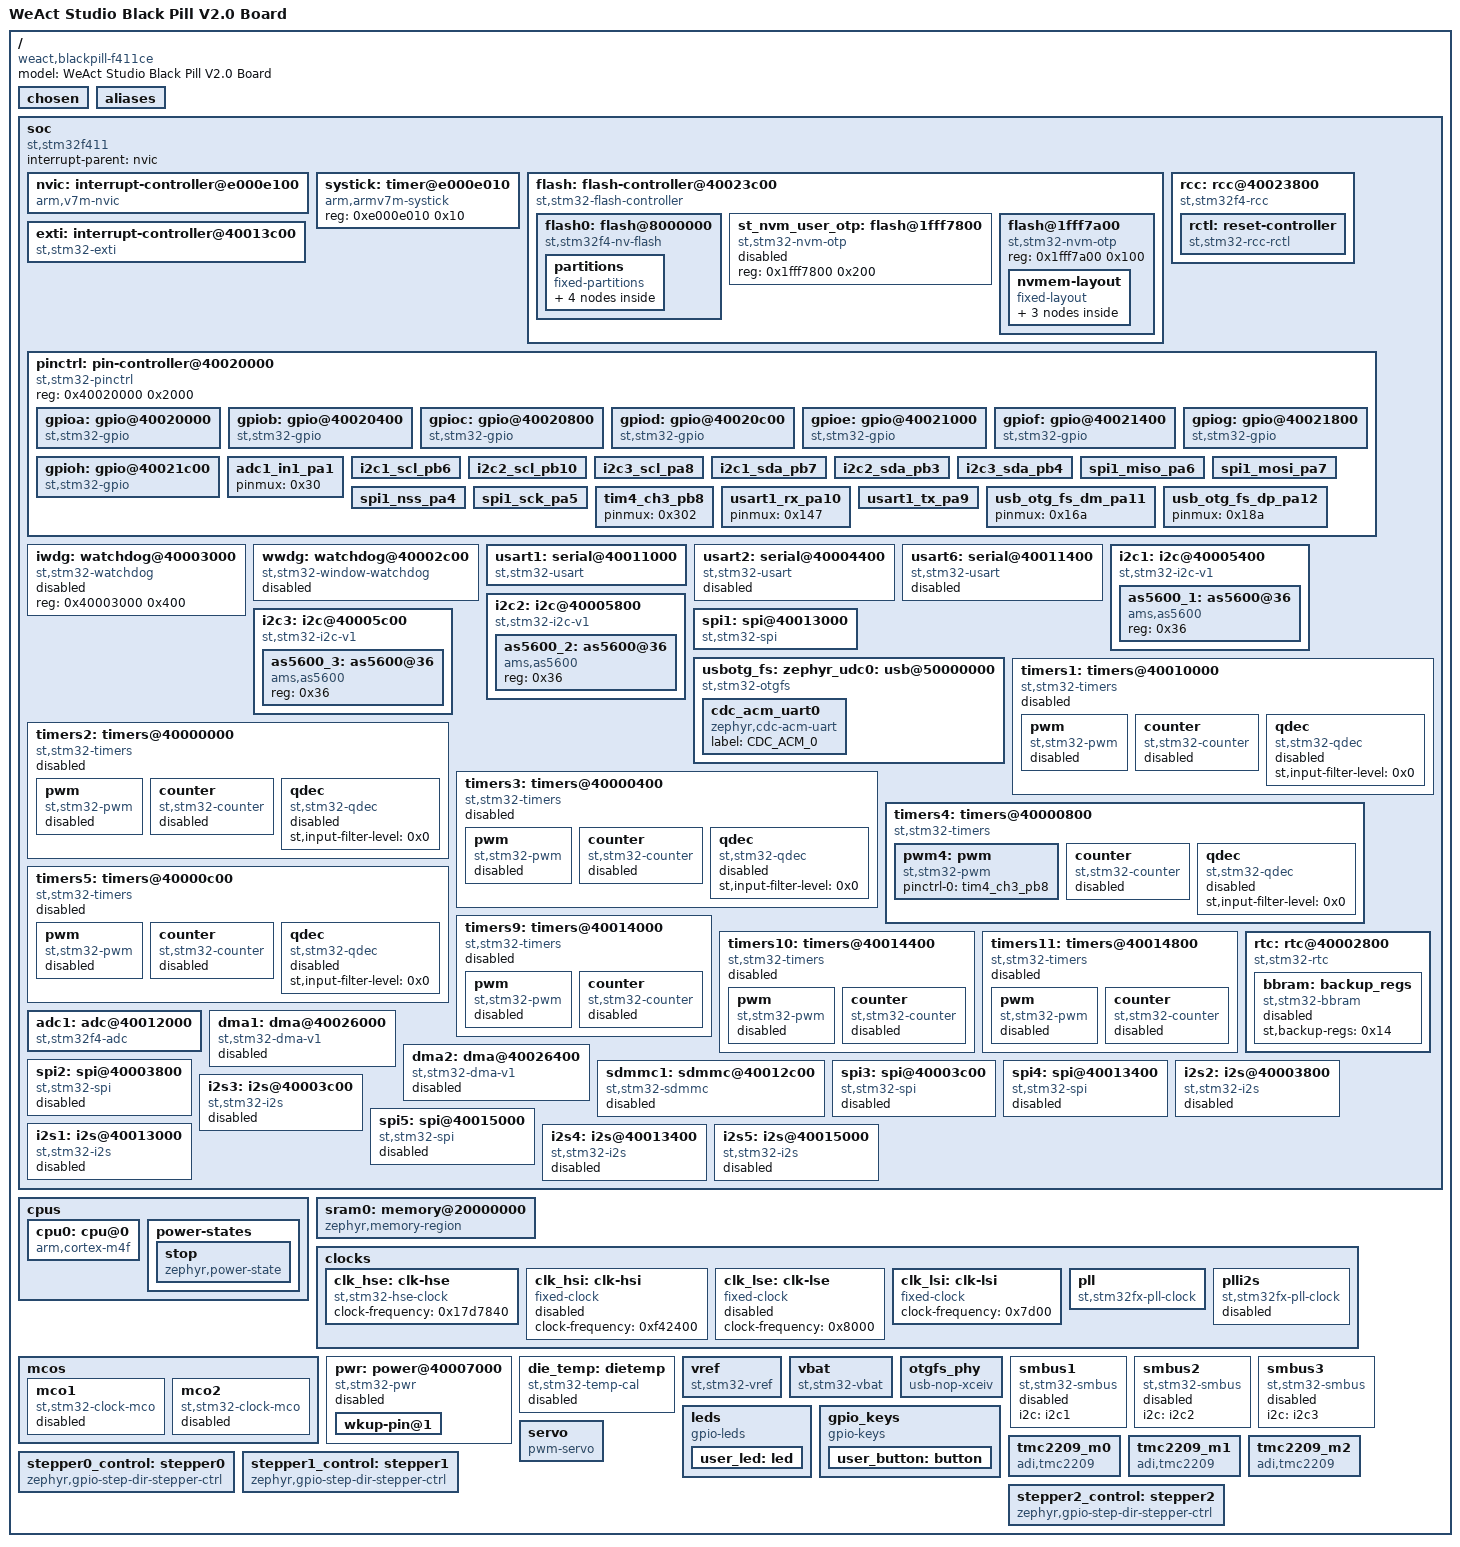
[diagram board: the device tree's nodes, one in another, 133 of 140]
/dts-v1/;

/* node '/' defined in zephyr/dts/common/skeleton.dtsi:9 */
/ {
	#address-cells = < 0x1 >;                     /* in zephyr/dts/common/skeleton.dtsi:10 */
	#size-cells = < 0x1 >;                        /* in zephyr/dts/common/skeleton.dtsi:11 */
	model = "WeAct Studio Black Pill V2.0 Board"; /* in zephyr/boards/weact/blackpill_f411ce/blackpill_f411ce.dts:14 */
	compatible = "weact,blackpill-f411ce";        /* in zephyr/boards/weact/blackpill_f411ce/blackpill_f411ce.dts:15 */

	/* node '/chosen' defined in zephyr/dts/common/skeleton.dtsi:13 */
	chosen {
		zephyr,flash-controller = &flash;     /* in zephyr/dts/arm/st/f4/stm32f4.dtsi:26 */
		zephyr,system-timer-companion = &rtc; /* in zephyr/dts/arm/st/f4/stm32f4.dtsi:27 */
		zephyr,sram = &sram0;                 /* in zephyr/boards/weact/blackpill_f411ce/blackpill_f411ce.dts:20 */
		zephyr,flash = &flash0;               /* in zephyr/boards/weact/blackpill_f411ce/blackpill_f411ce.dts:21 */
		zephyr,console = &cdc_acm_uart0;      /* in joint_microros_tmc2209_gripper_as5600/boards/blackpill_f411ce.overlay:137 */
		zephyr,shell-uart = &cdc_acm_uart0;   /* in joint_microros_tmc2209_gripper_as5600/boards/blackpill_f411ce.overlay:138 */
	};

	/* node '/aliases' defined in zephyr/dts/common/skeleton.dtsi:15 */
	aliases {
		led0 = &user_led;             /* in zephyr/boards/weact/blackpill_f411ce/blackpill_f411ce.dts:44 */
		sw0 = &user_button;           /* in zephyr/boards/weact/blackpill_f411ce/blackpill_f411ce.dts:45 */
		volt-sensor0 = &vref;         /* in zephyr/boards/weact/blackpill_f411ce/blackpill_f411ce.dts:46 */
		volt-sensor1 = &vbat;         /* in zephyr/boards/weact/blackpill_f411ce/blackpill_f411ce.dts:47 */
		stepper0 = &stepper0_control; /* in joint_microros_tmc2209_gripper_as5600/boards/blackpill_f411ce.overlay:82 */
		stepper1 = &stepper1_control; /* in joint_microros_tmc2209_gripper_as5600/boards/blackpill_f411ce.overlay:83 */
		stepper2 = &stepper2_control; /* in joint_microros_tmc2209_gripper_as5600/boards/blackpill_f411ce.overlay:84 */
	};

	/* node '/soc' defined in zephyr/dts/arm/armv7-m.dtsi:6 */
	soc {
		#address-cells = < 0x1 >;     /* in zephyr/dts/arm/armv7-m.dtsi:7 */
		#size-cells = < 0x1 >;        /* in zephyr/dts/arm/armv7-m.dtsi:8 */
		interrupt-parent = < &nvic >; /* in zephyr/dts/arm/armv7-m.dtsi:10 */
		ranges;                       /* in zephyr/dts/arm/armv7-m.dtsi:11 */
		compatible = "st,stm32f411",
		             "st,stm32f4",
		             "simple-bus";    /* in zephyr/dts/arm/st/f4/stm32f411.dtsi:11 */

		/* node '/soc/interrupt-controller@e000e100' defined in zephyr/dts/arm/armv7-m.dtsi:13 */
		nvic: interrupt-controller@e000e100 {
			#address-cells = < 0x1 >;            /* in zephyr/dts/arm/armv7-m.dtsi:14 */
			compatible = "arm,v7m-nvic";         /* in zephyr/dts/arm/armv7-m.dtsi:15 */
			reg = < 0xe000e100 0xc00 >;          /* in zephyr/dts/arm/armv7-m.dtsi:16 */
			interrupt-controller;                /* in zephyr/dts/arm/armv7-m.dtsi:17 */
			#interrupt-cells = < 0x2 >;          /* in zephyr/dts/arm/armv7-m.dtsi:18 */
			arm,num-irq-priority-bits = < 0x4 >; /* in zephyr/dts/arm/st/f4/stm32f4.dtsi:727 */
			phandle = < 0x1 >;                   /* in zephyr/dts/arm/armv7-m.dtsi:10 */
		};

		/* node '/soc/timer@e000e010' defined in zephyr/dts/arm/armv7-m.dtsi:21 */
		systick: timer@e000e010 {
			compatible = "arm,armv7m-systick"; /* in zephyr/dts/arm/armv7-m.dtsi:22 */
			reg = < 0xe000e010 0x10 >;         /* in zephyr/dts/arm/armv7-m.dtsi:23 */
		};

		/* node '/soc/flash-controller@40023c00' defined in zephyr/dts/arm/st/f4/stm32f4.dtsi:112 */
		flash: flash-controller@40023c00 {
			compatible = "st,stm32-flash-controller",
			             "st,stm32f4-flash-controller"; /* in zephyr/dts/arm/st/f4/stm32f4.dtsi:113 */
			reg = < 0x40023c00 0x400 >;                 /* in zephyr/dts/arm/st/f4/stm32f4.dtsi:114 */
			interrupts = < 0x4 0x0 >;                   /* in zephyr/dts/arm/st/f4/stm32f4.dtsi:115 */
			#address-cells = < 0x1 >;                   /* in zephyr/dts/arm/st/f4/stm32f4.dtsi:117 */
			#size-cells = < 0x1 >;                      /* in zephyr/dts/arm/st/f4/stm32f4.dtsi:118 */

			/* node '/soc/flash-controller@40023c00/flash@8000000' defined in zephyr/dts/arm/st/f4/stm32f4.dtsi:120 */
			flash0: flash@8000000 {
				compatible = "st,stm32f4-nv-flash",
				             "st,stm32-nv-flash",
				             "soc-nv-flash";        /* in zephyr/dts/arm/st/f4/stm32f4.dtsi:121 */
				write-block-size = < 0x1 >;         /* in zephyr/dts/arm/st/f4/stm32f4.dtsi:124 */
				max-erase-time = < 0xfa0 >;         /* in zephyr/dts/arm/st/f4/stm32f4.dtsi:126 */
				reg = < 0x8000000 0x80000 >;        /* in zephyr/dts/arm/st/f4/stm32f411Xe.dtsi:17 */

				/* node '/soc/flash-controller@40023c00/flash@8000000/partitions' defined in zephyr/boards/weact/blackpill_f411ce/blackpill_f411ce.dts:52 */
				partitions {
					compatible = "fixed-partitions"; /* in zephyr/boards/weact/blackpill_f411ce/blackpill_f411ce.dts:53 */
					#address-cells = < 0x1 >;        /* in zephyr/boards/weact/blackpill_f411ce/blackpill_f411ce.dts:54 */
					#size-cells = < 0x1 >;           /* in zephyr/boards/weact/blackpill_f411ce/blackpill_f411ce.dts:55 */

					/* node '/soc/flash-controller@40023c00/flash@8000000/partitions/partition@0' defined in zephyr/boards/weact/blackpill_f411ce/blackpill_f411ce.dts:57 */
					boot_partition: partition@0 {
						label = "mcuboot";    /* in zephyr/boards/weact/blackpill_f411ce/blackpill_f411ce.dts:58 */
						reg = < 0x0 0x8000 >; /* in zephyr/boards/weact/blackpill_f411ce/blackpill_f411ce.dts:59 */
						read-only;            /* in zephyr/boards/weact/blackpill_f411ce/blackpill_f411ce.dts:60 */
					};

					/* node '/soc/flash-controller@40023c00/flash@8000000/partitions/partition@20000' defined in zephyr/boards/weact/blackpill_f411ce/blackpill_f411ce.dts:69 */
					slot0_partition: partition@20000 {
						label = "image-0";         /* in zephyr/boards/weact/blackpill_f411ce/blackpill_f411ce.dts:70 */
						reg = < 0x20000 0x20000 >; /* in zephyr/boards/weact/blackpill_f411ce/blackpill_f411ce.dts:71 */
					};

					/* node '/soc/flash-controller@40023c00/flash@8000000/partitions/partition@40000' defined in zephyr/boards/weact/blackpill_f411ce/blackpill_f411ce.dts:74 */
					slot1_partition: partition@40000 {
						label = "image-1";         /* in zephyr/boards/weact/blackpill_f411ce/blackpill_f411ce.dts:75 */
						reg = < 0x40000 0x20000 >; /* in zephyr/boards/weact/blackpill_f411ce/blackpill_f411ce.dts:76 */
					};

					/* node '/soc/flash-controller@40023c00/flash@8000000/partitions/partition@60000' defined in zephyr/boards/weact/blackpill_f411ce/blackpill_f411ce.dts:79 */
					scratch_partition: partition@60000 {
						label = "image-scratch";   /* in zephyr/boards/weact/blackpill_f411ce/blackpill_f411ce.dts:80 */
						reg = < 0x60000 0x20000 >; /* in zephyr/boards/weact/blackpill_f411ce/blackpill_f411ce.dts:81 */
					};
				};
			};

			/* node '/soc/flash-controller@40023c00/flash@1fff7800' defined in zephyr/dts/arm/st/f4/stm32f4.dtsi:129 */
			st_nvm_user_otp: flash@1fff7800 {
				compatible = "st,stm32-nvm-otp"; /* in zephyr/dts/arm/st/f4/stm32f4.dtsi:130 */
				reg = < 0x1fff7800 0x200 >;      /* in zephyr/dts/arm/st/f4/stm32f4.dtsi:131 */
				status = "disabled";             /* in zephyr/dts/arm/st/f4/stm32f4.dtsi:132 */
			};

			/* node '/soc/flash-controller@40023c00/flash@1fff7a00' defined in zephyr/dts/arm/st/f4/stm32f4.dtsi:146 */
			flash@1fff7a00 {
				compatible = "st,stm32-nvm-otp"; /* in zephyr/dts/arm/st/f4/stm32f4.dtsi:147 */
				reg = < 0x1fff7a00 0x100 >;      /* in zephyr/dts/arm/st/f4/stm32f4.dtsi:148 */

				/* node '/soc/flash-controller@40023c00/flash@1fff7a00/nvmem-layout' defined in zephyr/dts/arm/st/f4/stm32f4.dtsi:150 */
				nvmem-layout {
					compatible = "fixed-layout"; /* in zephyr/dts/arm/st/f4/stm32f4.dtsi:151 */
					#address-cells = < 0x1 >;    /* in zephyr/dts/arm/st/f4/stm32f4.dtsi:152 */
					#size-cells = < 0x1 >;       /* in zephyr/dts/arm/st/f4/stm32f4.dtsi:153 */

					/* node '/soc/flash-controller@40023c00/flash@1fff7a00/nvmem-layout/vrefint@2a' defined in zephyr/dts/arm/st/f4/stm32f4.dtsi:155 */
					vrefint_otp: vrefint@2a {
						reg = < 0x2a 0x2 >;          /* in zephyr/dts/arm/st/f4/stm32f4.dtsi:156 */
						#nvmem-cell-cells = < 0x0 >; /* in zephyr/dts/arm/st/f4/stm32f4.dtsi:157 */
						read-only;                   /* in zephyr/dts/arm/st/f4/stm32f4.dtsi:158 */
						phandle = < 0x1e >;          /* in zephyr/dts/arm/st/f4/stm32f4.dtsi:683 */
					};

					/* node '/soc/flash-controller@40023c00/flash@1fff7a00/nvmem-layout/ts-cal1@2c' defined in zephyr/dts/arm/st/f4/stm32f4.dtsi:161 */
					ts_cal1_otp: ts-cal1@2c {
						reg = < 0x2c 0x2 >;          /* in zephyr/dts/arm/st/f4/stm32f4.dtsi:162 */
						#nvmem-cell-cells = < 0x0 >; /* in zephyr/dts/arm/st/f4/stm32f4.dtsi:163 */
						read-only;                   /* in zephyr/dts/arm/st/f4/stm32f4.dtsi:164 */
						phandle = < 0x1b >;          /* in zephyr/dts/arm/st/f4/stm32f4.dtsi:672 */
					};

					/* node '/soc/flash-controller@40023c00/flash@1fff7a00/nvmem-layout/ts-cal2@2e' defined in zephyr/dts/arm/st/f4/stm32f4.dtsi:167 */
					ts_cal2_otp: ts-cal2@2e {
						reg = < 0x2e 0x2 >;          /* in zephyr/dts/arm/st/f4/stm32f4.dtsi:168 */
						#nvmem-cell-cells = < 0x0 >; /* in zephyr/dts/arm/st/f4/stm32f4.dtsi:169 */
						read-only;                   /* in zephyr/dts/arm/st/f4/stm32f4.dtsi:170 */
						phandle = < 0x1c >;          /* in zephyr/dts/arm/st/f4/stm32f4.dtsi:672 */
					};
				};
			};
		};

		/* node '/soc/rcc@40023800' defined in zephyr/dts/arm/st/f4/stm32f4.dtsi:176 */
		rcc: rcc@40023800 {
			compatible = "st,stm32f4-rcc";   /* in zephyr/dts/arm/st/f4/stm32f4.dtsi:177 */
			#clock-cells = < 0x2 >;          /* in zephyr/dts/arm/st/f4/stm32f4.dtsi:178 */
			reg = < 0x40023800 0x400 >;      /* in zephyr/dts/arm/st/f4/stm32f4.dtsi:179 */
			clocks = < &pll >;               /* in zephyr/boards/weact/blackpill_f411ce/blackpill_f411ce.dts:156 */
			clock-frequency = < 0x5b8d800 >; /* in zephyr/boards/weact/blackpill_f411ce/blackpill_f411ce.dts:157 */
			ahb-prescaler = < 0x1 >;         /* in zephyr/boards/weact/blackpill_f411ce/blackpill_f411ce.dts:158 */
			apb1-prescaler = < 0x2 >;        /* in zephyr/boards/weact/blackpill_f411ce/blackpill_f411ce.dts:159 */
			apb2-prescaler = < 0x1 >;        /* in zephyr/boards/weact/blackpill_f411ce/blackpill_f411ce.dts:160 */
			phandle = < 0x3 >;               /* in zephyr/dts/arm/st/f4/stm32f4.dtsi:193 */

			/* node '/soc/rcc@40023800/reset-controller' defined in zephyr/dts/arm/st/f4/stm32f4.dtsi:181 */
			rctl: reset-controller {
				compatible = "st,stm32-rcc-rctl"; /* in zephyr/dts/arm/st/f4/stm32f4.dtsi:182 */
				#reset-cells = < 0x1 >;           /* in zephyr/dts/arm/st/f4/stm32f4.dtsi:183 */
				phandle = < 0x4 >;                /* in zephyr/dts/arm/st/f4/stm32f4.dtsi:292 */
			};
		};

		/* node '/soc/interrupt-controller@40013c00' defined in zephyr/dts/arm/st/f4/stm32f4.dtsi:187 */
		exti: interrupt-controller@40013c00 {
			compatible = "st,stm32-exti";  /* in zephyr/dts/arm/st/f4/stm32f4.dtsi:188 */
			interrupt-controller;          /* in zephyr/dts/arm/st/f4/stm32f4.dtsi:189 */
			#interrupt-cells = < 0x1 >;    /* in zephyr/dts/arm/st/f4/stm32f4.dtsi:190 */
			#address-cells = < 0x0 >;      /* in zephyr/dts/arm/st/f4/stm32f4.dtsi:191 */
			reg = < 0x40013c00 0x400 >;    /* in zephyr/dts/arm/st/f4/stm32f4.dtsi:192 */
			clocks = < &rcc 0x44 0x4000 >; /* in zephyr/dts/arm/st/f4/stm32f4.dtsi:193 */
			num-lines = < 0x20 >;          /* in zephyr/dts/arm/st/f4/stm32f4.dtsi:194 */
			interrupts = < 0x6 0x0 >,
			             < 0x7 0x0 >,
			             < 0x8 0x0 >,
			             < 0x9 0x0 >,
			             < 0xa 0x0 >,
			             < 0x17 0x0 >,
			             < 0x28 0x0 >;     /* in zephyr/dts/arm/st/f4/stm32f4.dtsi:195 */
			interrupt-names = "line0",
			                  "line1",
			                  "line2",
			                  "line3",
			                  "line4",
			                  "line5-9",
			                  "line10-15"; /* in zephyr/dts/arm/st/f4/stm32f4.dtsi:197 */
			line-ranges = < 0x0 0x1 >,
			              < 0x1 0x1 >,
			              < 0x2 0x1 >,
			              < 0x3 0x1 >,
			              < 0x4 0x1 >,
			              < 0x5 0x5 >,
			              < 0xa 0x6 >;     /* in zephyr/dts/arm/st/f4/stm32f4.dtsi:199 */
		};

		/* node '/soc/pin-controller@40020000' defined in zephyr/dts/arm/st/f4/stm32f4.dtsi:203 */
		pinctrl: pin-controller@40020000 {
			compatible = "st,stm32-pinctrl"; /* in zephyr/dts/arm/st/f4/stm32f4.dtsi:204 */
			#address-cells = < 0x1 >;        /* in zephyr/dts/arm/st/f4/stm32f4.dtsi:205 */
			#size-cells = < 0x1 >;           /* in zephyr/dts/arm/st/f4/stm32f4.dtsi:206 */
			reg = < 0x40020000 0x2000 >;     /* in zephyr/dts/arm/st/f4/stm32f4.dtsi:207 */

			/* node '/soc/pin-controller@40020000/gpio@40020000' defined in zephyr/dts/arm/st/f4/stm32f4.dtsi:209 */
			gpioa: gpio@40020000 {
				compatible = "st,stm32-gpio"; /* in zephyr/dts/arm/st/f4/stm32f4.dtsi:210 */
				gpio-controller;              /* in zephyr/dts/arm/st/f4/stm32f4.dtsi:211 */
				#gpio-cells = < 0x2 >;        /* in zephyr/dts/arm/st/f4/stm32f4.dtsi:212 */
				reg = < 0x40020000 0x400 >;   /* in zephyr/dts/arm/st/f4/stm32f4.dtsi:213 */
				clocks = < &rcc 0x30 0x1 >;   /* in zephyr/dts/arm/st/f4/stm32f4.dtsi:214 */
				phandle = < 0x1a >;           /* in zephyr/dts/arm/st/f4/stm32f4.dtsi:666 */
			};

			/* node '/soc/pin-controller@40020000/gpio@40020400' defined in zephyr/dts/arm/st/f4/stm32f4.dtsi:217 */
			gpiob: gpio@40020400 {
				compatible = "st,stm32-gpio"; /* in zephyr/dts/arm/st/f4/stm32f4.dtsi:218 */
				gpio-controller;              /* in zephyr/dts/arm/st/f4/stm32f4.dtsi:219 */
				#gpio-cells = < 0x2 >;        /* in zephyr/dts/arm/st/f4/stm32f4.dtsi:220 */
				reg = < 0x40020400 0x400 >;   /* in zephyr/dts/arm/st/f4/stm32f4.dtsi:221 */
				clocks = < &rcc 0x30 0x2 >;   /* in zephyr/dts/arm/st/f4/stm32f4.dtsi:222 */
			};

			/* node '/soc/pin-controller@40020000/gpio@40020800' defined in zephyr/dts/arm/st/f4/stm32f4.dtsi:225 */
			gpioc: gpio@40020800 {
				compatible = "st,stm32-gpio"; /* in zephyr/dts/arm/st/f4/stm32f4.dtsi:226 */
				gpio-controller;              /* in zephyr/dts/arm/st/f4/stm32f4.dtsi:227 */
				#gpio-cells = < 0x2 >;        /* in zephyr/dts/arm/st/f4/stm32f4.dtsi:228 */
				reg = < 0x40020800 0x400 >;   /* in zephyr/dts/arm/st/f4/stm32f4.dtsi:229 */
				clocks = < &rcc 0x30 0x4 >;   /* in zephyr/dts/arm/st/f4/stm32f4.dtsi:230 */
				phandle = < 0x22 >;           /* in zephyr/boards/weact/blackpill_f411ce/blackpill_f411ce.dts:28 */
			};

			/* node '/soc/pin-controller@40020000/gpio@40020c00' defined in zephyr/dts/arm/st/f4/stm32f4.dtsi:233 */
			gpiod: gpio@40020c00 {
				compatible = "st,stm32-gpio"; /* in zephyr/dts/arm/st/f4/stm32f4.dtsi:234 */
				gpio-controller;              /* in zephyr/dts/arm/st/f4/stm32f4.dtsi:235 */
				#gpio-cells = < 0x2 >;        /* in zephyr/dts/arm/st/f4/stm32f4.dtsi:236 */
				reg = < 0x40020c00 0x400 >;   /* in zephyr/dts/arm/st/f4/stm32f4.dtsi:237 */
				clocks = < &rcc 0x30 0x8 >;   /* in zephyr/dts/arm/st/f4/stm32f4.dtsi:238 */
			};

			/* node '/soc/pin-controller@40020000/gpio@40021000' defined in zephyr/dts/arm/st/f4/stm32f4.dtsi:241 */
			gpioe: gpio@40021000 {
				compatible = "st,stm32-gpio"; /* in zephyr/dts/arm/st/f4/stm32f4.dtsi:242 */
				gpio-controller;              /* in zephyr/dts/arm/st/f4/stm32f4.dtsi:243 */
				#gpio-cells = < 0x2 >;        /* in zephyr/dts/arm/st/f4/stm32f4.dtsi:244 */
				reg = < 0x40021000 0x400 >;   /* in zephyr/dts/arm/st/f4/stm32f4.dtsi:245 */
				clocks = < &rcc 0x30 0x10 >;  /* in zephyr/dts/arm/st/f4/stm32f4.dtsi:246 */
			};

			/* node '/soc/pin-controller@40020000/gpio@40021400' defined in zephyr/dts/arm/st/f4/stm32f4.dtsi:249 */
			gpiof: gpio@40021400 {
				compatible = "st,stm32-gpio"; /* in zephyr/dts/arm/st/f4/stm32f4.dtsi:250 */
				gpio-controller;              /* in zephyr/dts/arm/st/f4/stm32f4.dtsi:251 */
				#gpio-cells = < 0x2 >;        /* in zephyr/dts/arm/st/f4/stm32f4.dtsi:252 */
				reg = < 0x40021400 0x400 >;   /* in zephyr/dts/arm/st/f4/stm32f4.dtsi:253 */
				clocks = < &rcc 0x30 0x20 >;  /* in zephyr/dts/arm/st/f4/stm32f4.dtsi:254 */
			};

			/* node '/soc/pin-controller@40020000/gpio@40021800' defined in zephyr/dts/arm/st/f4/stm32f4.dtsi:257 */
			gpiog: gpio@40021800 {
				compatible = "st,stm32-gpio"; /* in zephyr/dts/arm/st/f4/stm32f4.dtsi:258 */
				gpio-controller;              /* in zephyr/dts/arm/st/f4/stm32f4.dtsi:259 */
				#gpio-cells = < 0x2 >;        /* in zephyr/dts/arm/st/f4/stm32f4.dtsi:260 */
				reg = < 0x40021800 0x400 >;   /* in zephyr/dts/arm/st/f4/stm32f4.dtsi:261 */
				clocks = < &rcc 0x30 0x40 >;  /* in zephyr/dts/arm/st/f4/stm32f4.dtsi:262 */
			};

			/* node '/soc/pin-controller@40020000/gpio@40021c00' defined in zephyr/dts/arm/st/f4/stm32f4.dtsi:265 */
			gpioh: gpio@40021c00 {
				compatible = "st,stm32-gpio"; /* in zephyr/dts/arm/st/f4/stm32f4.dtsi:266 */
				gpio-controller;              /* in zephyr/dts/arm/st/f4/stm32f4.dtsi:267 */
				#gpio-cells = < 0x2 >;        /* in zephyr/dts/arm/st/f4/stm32f4.dtsi:268 */
				reg = < 0x40021c00 0x400 >;   /* in zephyr/dts/arm/st/f4/stm32f4.dtsi:269 */
				clocks = < &rcc 0x30 0x80 >;  /* in zephyr/dts/arm/st/f4/stm32f4.dtsi:270 */
			};

			/* node '/soc/pin-controller@40020000/adc1_in1_pa1' defined in modules/hal/stm32/dts/st/f4/stm32f411c(c-e)ux-pinctrl.dtsi:17 */
			adc1_in1_pa1: adc1_in1_pa1 {
				pinmux = < 0x30 >;  /* in modules/hal/stm32/dts/st/f4/stm32f411c(c-e)ux-pinctrl.dtsi:18 */
				phandle = < 0x15 >; /* in zephyr/boards/weact/blackpill_f411ce/blackpill_f411ce.dts:130 */
			};

			/* node '/soc/pin-controller@40020000/i2c1_scl_pb6' defined in modules/hal/stm32/dts/st/f4/stm32f411c(c-e)ux-pinctrl.dtsi:201 */
			i2c1_scl_pb6: i2c1_scl_pb6 {
				pinmux = < 0x2c4 >; /* in modules/hal/stm32/dts/st/f4/stm32f411c(c-e)ux-pinctrl.dtsi:202 */
				bias-pull-up;       /* in modules/hal/stm32/dts/st/f4/stm32f411c(c-e)ux-pinctrl.dtsi:203 */
				drive-open-drain;   /* in modules/hal/stm32/dts/st/f4/stm32f411c(c-e)ux-pinctrl.dtsi:204 */
				phandle = < 0x7 >;  /* in joint_microros_tmc2209_gripper_as5600/boards/blackpill_f411ce.overlay:22 */
			};

			/* node '/soc/pin-controller@40020000/i2c2_scl_pb10' defined in modules/hal/stm32/dts/st/f4/stm32f411c(c-e)ux-pinctrl.dtsi:213 */
			i2c2_scl_pb10: i2c2_scl_pb10 {
				pinmux = < 0x344 >; /* in modules/hal/stm32/dts/st/f4/stm32f411c(c-e)ux-pinctrl.dtsi:214 */
				bias-pull-up;       /* in modules/hal/stm32/dts/st/f4/stm32f411c(c-e)ux-pinctrl.dtsi:215 */
				drive-open-drain;   /* in modules/hal/stm32/dts/st/f4/stm32f411c(c-e)ux-pinctrl.dtsi:216 */
				phandle = < 0x9 >;  /* in joint_microros_tmc2209_gripper_as5600/boards/blackpill_f411ce.overlay:34 */
			};

			/* node '/soc/pin-controller@40020000/i2c3_scl_pa8' defined in modules/hal/stm32/dts/st/f4/stm32f411c(c-e)ux-pinctrl.dtsi:219 */
			i2c3_scl_pa8: i2c3_scl_pa8 {
				pinmux = < 0x104 >; /* in modules/hal/stm32/dts/st/f4/stm32f411c(c-e)ux-pinctrl.dtsi:220 */
				bias-pull-up;       /* in modules/hal/stm32/dts/st/f4/stm32f411c(c-e)ux-pinctrl.dtsi:221 */
				drive-open-drain;   /* in modules/hal/stm32/dts/st/f4/stm32f411c(c-e)ux-pinctrl.dtsi:222 */
				phandle = < 0xb >;  /* in joint_microros_tmc2209_gripper_as5600/boards/blackpill_f411ce.overlay:47 */
			};

			/* node '/soc/pin-controller@40020000/i2c1_sda_pb7' defined in modules/hal/stm32/dts/st/f4/stm32f411c(c-e)ux-pinctrl.dtsi:227 */
			i2c1_sda_pb7: i2c1_sda_pb7 {
				pinmux = < 0x2e4 >; /* in modules/hal/stm32/dts/st/f4/stm32f411c(c-e)ux-pinctrl.dtsi:228 */
				bias-pull-up;       /* in modules/hal/stm32/dts/st/f4/stm32f411c(c-e)ux-pinctrl.dtsi:229 */
				drive-open-drain;   /* in modules/hal/stm32/dts/st/f4/stm32f411c(c-e)ux-pinctrl.dtsi:230 */
				phandle = < 0x8 >;  /* in joint_microros_tmc2209_gripper_as5600/boards/blackpill_f411ce.overlay:22 */
			};

			/* node '/soc/pin-controller@40020000/i2c2_sda_pb3' defined in modules/hal/stm32/dts/st/f4/stm32f411c(c-e)ux-pinctrl.dtsi:239 */
			i2c2_sda_pb3: i2c2_sda_pb3 {
				pinmux = < 0x269 >; /* in modules/hal/stm32/dts/st/f4/stm32f411c(c-e)ux-pinctrl.dtsi:240 */
				bias-pull-up;       /* in modules/hal/stm32/dts/st/f4/stm32f411c(c-e)ux-pinctrl.dtsi:241 */
				drive-open-drain;   /* in modules/hal/stm32/dts/st/f4/stm32f411c(c-e)ux-pinctrl.dtsi:242 */
				phandle = < 0xa >;  /* in joint_microros_tmc2209_gripper_as5600/boards/blackpill_f411ce.overlay:34 */
			};

			/* node '/soc/pin-controller@40020000/i2c3_sda_pb4' defined in modules/hal/stm32/dts/st/f4/stm32f411c(c-e)ux-pinctrl.dtsi:251 */
			i2c3_sda_pb4: i2c3_sda_pb4 {
				pinmux = < 0x289 >; /* in modules/hal/stm32/dts/st/f4/stm32f411c(c-e)ux-pinctrl.dtsi:252 */
				bias-pull-up;       /* in modules/hal/stm32/dts/st/f4/stm32f411c(c-e)ux-pinctrl.dtsi:253 */
				drive-open-drain;   /* in modules/hal/stm32/dts/st/f4/stm32f411c(c-e)ux-pinctrl.dtsi:254 */
				phandle = < 0xc >;  /* in joint_microros_tmc2209_gripper_as5600/boards/blackpill_f411ce.overlay:47 */
			};

			/* node '/soc/pin-controller@40020000/spi1_miso_pa6' defined in modules/hal/stm32/dts/st/f4/stm32f411c(c-e)ux-pinctrl.dtsi:502 */
			spi1_miso_pa6: spi1_miso_pa6 {
				pinmux = < 0xc5 >;             /* in modules/hal/stm32/dts/st/f4/stm32f411c(c-e)ux-pinctrl.dtsi:503 */
				bias-pull-down;                /* in modules/hal/stm32/dts/st/f4/stm32f411c(c-e)ux-pinctrl.dtsi:504 */
				slew-rate = "very-high-speed"; /* in modules/hal/stm32/dts/st/f4/stm32f411c(c-e)ux-pinctrl.dtsi:505 */
				phandle = < 0xf >;             /* in zephyr/boards/weact/blackpill_f411ce/blackpill_f411ce.dts:111 */
			};

			/* node '/soc/pin-controller@40020000/spi1_mosi_pa7' defined in modules/hal/stm32/dts/st/f4/stm32f411c(c-e)ux-pinctrl.dtsi:540 */
			spi1_mosi_pa7: spi1_mosi_pa7 {
				pinmux = < 0xe5 >;             /* in modules/hal/stm32/dts/st/f4/stm32f411c(c-e)ux-pinctrl.dtsi:541 */
				bias-pull-down;                /* in modules/hal/stm32/dts/st/f4/stm32f411c(c-e)ux-pinctrl.dtsi:542 */
				slew-rate = "very-high-speed"; /* in modules/hal/stm32/dts/st/f4/stm32f411c(c-e)ux-pinctrl.dtsi:543 */
				phandle = < 0x10 >;            /* in zephyr/boards/weact/blackpill_f411ce/blackpill_f411ce.dts:111 */
			};

			/* node '/soc/pin-controller@40020000/spi1_nss_pa4' defined in modules/hal/stm32/dts/st/f4/stm32f411c(c-e)ux-pinctrl.dtsi:584 */
			spi1_nss_pa4: spi1_nss_pa4 {
				pinmux = < 0x85 >;             /* in modules/hal/stm32/dts/st/f4/stm32f411c(c-e)ux-pinctrl.dtsi:585 */
				bias-pull-up;                  /* in modules/hal/stm32/dts/st/f4/stm32f411c(c-e)ux-pinctrl.dtsi:586 */
				slew-rate = "very-high-speed"; /* in modules/hal/stm32/dts/st/f4/stm32f411c(c-e)ux-pinctrl.dtsi:587 */
				phandle = < 0xe >;             /* in zephyr/boards/weact/blackpill_f411ce/blackpill_f411ce.dts:111 */
			};

			/* node '/soc/pin-controller@40020000/spi1_sck_pa5' defined in modules/hal/stm32/dts/st/f4/stm32f411c(c-e)ux-pinctrl.dtsi:634 */
			spi1_sck_pa5: spi1_sck_pa5 {
				pinmux = < 0xa5 >;             /* in modules/hal/stm32/dts/st/f4/stm32f411c(c-e)ux-pinctrl.dtsi:635 */
				bias-pull-down;                /* in modules/hal/stm32/dts/st/f4/stm32f411c(c-e)ux-pinctrl.dtsi:636 */
				slew-rate = "very-high-speed"; /* in modules/hal/stm32/dts/st/f4/stm32f411c(c-e)ux-pinctrl.dtsi:637 */
				phandle = < 0xd >;             /* in zephyr/boards/weact/blackpill_f411ce/blackpill_f411ce.dts:111 */
			};

			/* node '/soc/pin-controller@40020000/tim4_ch3_pb8' defined in modules/hal/stm32/dts/st/f4/stm32f411c(c-e)ux-pinctrl.dtsi:806 */
			tim4_ch3_pb8: tim4_ch3_pb8 {
				pinmux = < 0x302 >; /* in joint_microros_tmc2209_gripper_as5600/boards/blackpill_f411ce.overlay:63 */
				phandle = < 0x14 >; /* in joint_microros_tmc2209_gripper_as5600/boards/blackpill_f411ce.overlay:73 */
			};

			/* node '/soc/pin-controller@40020000/usart1_rx_pa10' defined in modules/hal/stm32/dts/st/f4/stm32f411c(c-e)ux-pinctrl.dtsi:864 */
			usart1_rx_pa10: usart1_rx_pa10 {
				pinmux = < 0x147 >; /* in modules/hal/stm32/dts/st/f4/stm32f411c(c-e)ux-pinctrl.dtsi:865 */
				phandle = < 0x6 >;  /* in zephyr/boards/weact/blackpill_f411ce/blackpill_f411ce.dts:97 */
			};

			/* node '/soc/pin-controller@40020000/usart1_tx_pa9' defined in modules/hal/stm32/dts/st/f4/stm32f411c(c-e)ux-pinctrl.dtsi:886 */
			usart1_tx_pa9: usart1_tx_pa9 {
				pinmux = < 0x127 >; /* in modules/hal/stm32/dts/st/f4/stm32f411c(c-e)ux-pinctrl.dtsi:887 */
				bias-pull-up;       /* in modules/hal/stm32/dts/st/f4/stm32f411c(c-e)ux-pinctrl.dtsi:888 */
				phandle = < 0x5 >;  /* in zephyr/boards/weact/blackpill_f411ce/blackpill_f411ce.dts:97 */
			};

			/* node '/soc/pin-controller@40020000/usb_otg_fs_dm_pa11' defined in modules/hal/stm32/dts/st/f4/stm32f411c(c-e)ux-pinctrl.dtsi:925 */
			usb_otg_fs_dm_pa11: usb_otg_fs_dm_pa11 {
				pinmux = < 0x16a >; /* in modules/hal/stm32/dts/st/f4/stm32f411c(c-e)ux-pinctrl.dtsi:926 */
				phandle = < 0x12 >; /* in joint_microros_tmc2209_gripper_as5600/boards/blackpill_f411ce.overlay:145 */
			};

			/* node '/soc/pin-controller@40020000/usb_otg_fs_dp_pa12' defined in modules/hal/stm32/dts/st/f4/stm32f411c(c-e)ux-pinctrl.dtsi:929 */
			usb_otg_fs_dp_pa12: usb_otg_fs_dp_pa12 {
				pinmux = < 0x18a >; /* in modules/hal/stm32/dts/st/f4/stm32f411c(c-e)ux-pinctrl.dtsi:930 */
				phandle = < 0x13 >; /* in joint_microros_tmc2209_gripper_as5600/boards/blackpill_f411ce.overlay:145 */
			};
		};

		/* node '/soc/watchdog@40003000' defined in zephyr/dts/arm/st/f4/stm32f4.dtsi:274 */
		iwdg: watchdog@40003000 {
			compatible = "st,stm32-watchdog"; /* in zephyr/dts/arm/st/f4/stm32f4.dtsi:275 */
			reg = < 0x40003000 0x400 >;       /* in zephyr/dts/arm/st/f4/stm32f4.dtsi:276 */
			status = "disabled";              /* in zephyr/dts/arm/st/f4/stm32f4.dtsi:277 */
		};

		/* node '/soc/watchdog@40002c00' defined in zephyr/dts/arm/st/f4/stm32f4.dtsi:280 */
		wwdg: watchdog@40002c00 {
			compatible = "st,stm32-window-watchdog"; /* in zephyr/dts/arm/st/f4/stm32f4.dtsi:281 */
			reg = < 0x40002c00 0x400 >;              /* in zephyr/dts/arm/st/f4/stm32f4.dtsi:282 */
			clocks = < &rcc 0x40 0x800 >;            /* in zephyr/dts/arm/st/f4/stm32f4.dtsi:283 */
			interrupts = < 0x0 0x7 >;                /* in zephyr/dts/arm/st/f4/stm32f4.dtsi:284 */
			status = "disabled";                     /* in zephyr/dts/arm/st/f4/stm32f4.dtsi:285 */
		};

		/* node '/soc/serial@40011000' defined in zephyr/dts/arm/st/f4/stm32f4.dtsi:288 */
		usart1: serial@40011000 {
			compatible = "st,stm32-usart",
			             "st,stm32-uart";                   /* in zephyr/dts/arm/st/f4/stm32f4.dtsi:289 */
			reg = < 0x40011000 0x400 >;                     /* in zephyr/dts/arm/st/f4/stm32f4.dtsi:290 */
			clocks = < &rcc 0x44 0x10 >;                    /* in zephyr/dts/arm/st/f4/stm32f4.dtsi:291 */
			resets = < &rctl 0x484 >;                       /* in zephyr/dts/arm/st/f4/stm32f4.dtsi:292 */
			interrupts = < 0x25 0x0 >;                      /* in zephyr/dts/arm/st/f4/stm32f4.dtsi:293 */
			pinctrl-0 = < &usart1_tx_pa9 &usart1_rx_pa10 >; /* in zephyr/boards/weact/blackpill_f411ce/blackpill_f411ce.dts:97 */
			pinctrl-names = "default";                      /* in zephyr/boards/weact/blackpill_f411ce/blackpill_f411ce.dts:98 */
			status = "okay";                                /* in zephyr/boards/weact/blackpill_f411ce/blackpill_f411ce.dts:99 */
			current-speed = < 0x1c200 >;                    /* in zephyr/boards/weact/blackpill_f411ce/blackpill_f411ce.dts:100 */
		};

		/* node '/soc/serial@40004400' defined in zephyr/dts/arm/st/f4/stm32f4.dtsi:297 */
		usart2: serial@40004400 {
			compatible = "st,stm32-usart",
			             "st,stm32-uart";   /* in zephyr/dts/arm/st/f4/stm32f4.dtsi:298 */
			reg = < 0x40004400 0x400 >;     /* in zephyr/dts/arm/st/f4/stm32f4.dtsi:299 */
			clocks = < &rcc 0x40 0x20000 >; /* in zephyr/dts/arm/st/f4/stm32f4.dtsi:300 */
			resets = < &rctl 0x411 >;       /* in zephyr/dts/arm/st/f4/stm32f4.dtsi:301 */
			interrupts = < 0x26 0x0 >;      /* in zephyr/dts/arm/st/f4/stm32f4.dtsi:302 */
			status = "disabled";            /* in zephyr/dts/arm/st/f4/stm32f4.dtsi:303 */
		};

		/* node '/soc/serial@40011400' defined in zephyr/dts/arm/st/f4/stm32f4.dtsi:306 */
		usart6: serial@40011400 {
			compatible = "st,stm32-usart",
			             "st,stm32-uart";  /* in zephyr/dts/arm/st/f4/stm32f4.dtsi:307 */
			reg = < 0x40011400 0x400 >;    /* in zephyr/dts/arm/st/f4/stm32f4.dtsi:308 */
			clocks = < &rcc 0x44 0x20 >;   /* in zephyr/dts/arm/st/f4/stm32f4.dtsi:309 */
			resets = < &rctl 0x485 >;      /* in zephyr/dts/arm/st/f4/stm32f4.dtsi:310 */
			interrupts = < 0x47 0x0 >;     /* in zephyr/dts/arm/st/f4/stm32f4.dtsi:311 */
			status = "disabled";           /* in zephyr/dts/arm/st/f4/stm32f4.dtsi:312 */
		};

		/* node '/soc/i2c@40005400' defined in zephyr/dts/arm/st/f4/stm32f4.dtsi:315 */
		i2c1: i2c@40005400 {
			compatible = "st,stm32-i2c-v1";              /* in zephyr/dts/arm/st/f4/stm32f4.dtsi:316 */
			#address-cells = < 0x1 >;                    /* in zephyr/dts/arm/st/f4/stm32f4.dtsi:318 */
			#size-cells = < 0x0 >;                       /* in zephyr/dts/arm/st/f4/stm32f4.dtsi:319 */
			reg = < 0x40005400 0x400 >;                  /* in zephyr/dts/arm/st/f4/stm32f4.dtsi:320 */
			clocks = < &rcc 0x40 0x200000 >;             /* in zephyr/dts/arm/st/f4/stm32f4.dtsi:321 */
			interrupts = < 0x1f 0x0 >,
			             < 0x20 0x0 >;                   /* in zephyr/dts/arm/st/f4/stm32f4.dtsi:322 */
			interrupt-names = "event",
			                  "error";                   /* in zephyr/dts/arm/st/f4/stm32f4.dtsi:323 */
			status = "okay";                             /* in joint_microros_tmc2209_gripper_as5600/boards/blackpill_f411ce.overlay:21 */
			pinctrl-0 = < &i2c1_scl_pb6 &i2c1_sda_pb7 >; /* in joint_microros_tmc2209_gripper_as5600/boards/blackpill_f411ce.overlay:22 */
			pinctrl-names = "default";                   /* in joint_microros_tmc2209_gripper_as5600/boards/blackpill_f411ce.overlay:23 */
			clock-frequency = < 0x186a0 >;               /* in joint_microros_tmc2209_gripper_as5600/boards/blackpill_f411ce.overlay:24 */
			phandle = < 0x1f >;                          /* in zephyr/dts/arm/st/f4/stm32f4.dtsi:705 */

			/* node '/soc/i2c@40005400/as5600@36' defined in joint_microros_tmc2209_gripper_as5600/boards/blackpill_f411ce.overlay:26 */
			as5600_1: as5600@36 {
				compatible = "ams,as5600"; /* in joint_microros_tmc2209_gripper_as5600/boards/blackpill_f411ce.overlay:27 */
				status = "okay";           /* in joint_microros_tmc2209_gripper_as5600/boards/blackpill_f411ce.overlay:28 */
				reg = < 0x36 >;            /* in joint_microros_tmc2209_gripper_as5600/boards/blackpill_f411ce.overlay:29 */
			};
		};

		/* node '/soc/i2c@40005800' defined in zephyr/dts/arm/st/f4/stm32f4.dtsi:327 */
		i2c2: i2c@40005800 {
			compatible = "st,stm32-i2c-v1";               /* in zephyr/dts/arm/st/f4/stm32f4.dtsi:328 */
			#address-cells = < 0x1 >;                     /* in zephyr/dts/arm/st/f4/stm32f4.dtsi:330 */
			#size-cells = < 0x0 >;                        /* in zephyr/dts/arm/st/f4/stm32f4.dtsi:331 */
			reg = < 0x40005800 0x400 >;                   /* in zephyr/dts/arm/st/f4/stm32f4.dtsi:332 */
			clocks = < &rcc 0x40 0x400000 >;              /* in zephyr/dts/arm/st/f4/stm32f4.dtsi:333 */
			interrupts = < 0x21 0x0 >,
			             < 0x22 0x0 >;                    /* in zephyr/dts/arm/st/f4/stm32f4.dtsi:334 */
			interrupt-names = "event",
			                  "error";                    /* in zephyr/dts/arm/st/f4/stm32f4.dtsi:335 */
			pinctrl-0 = < &i2c2_scl_pb10 &i2c2_sda_pb3 >; /* in joint_microros_tmc2209_gripper_as5600/boards/blackpill_f411ce.overlay:34 */
			pinctrl-names = "default";                    /* in joint_microros_tmc2209_gripper_as5600/boards/blackpill_f411ce.overlay:35 */
			status = "okay";                              /* in joint_microros_tmc2209_gripper_as5600/boards/blackpill_f411ce.overlay:36 */
			clock-frequency = < 0x186a0 >;                /* in joint_microros_tmc2209_gripper_as5600/boards/blackpill_f411ce.overlay:37 */
			phandle = < 0x20 >;                           /* in zephyr/dts/arm/st/f4/stm32f4.dtsi:713 */

			/* node '/soc/i2c@40005800/as5600@36' defined in joint_microros_tmc2209_gripper_as5600/boards/blackpill_f411ce.overlay:39 */
			as5600_2: as5600@36 {
				compatible = "ams,as5600"; /* in joint_microros_tmc2209_gripper_as5600/boards/blackpill_f411ce.overlay:40 */
				status = "okay";           /* in joint_microros_tmc2209_gripper_as5600/boards/blackpill_f411ce.overlay:41 */
				reg = < 0x36 >;            /* in joint_microros_tmc2209_gripper_as5600/boards/blackpill_f411ce.overlay:42 */
			};
		};

		/* node '/soc/i2c@40005c00' defined in zephyr/dts/arm/st/f4/stm32f4.dtsi:339 */
		i2c3: i2c@40005c00 {
			compatible = "st,stm32-i2c-v1";              /* in zephyr/dts/arm/st/f4/stm32f4.dtsi:340 */
			#address-cells = < 0x1 >;                    /* in zephyr/dts/arm/st/f4/stm32f4.dtsi:342 */
			#size-cells = < 0x0 >;                       /* in zephyr/dts/arm/st/f4/stm32f4.dtsi:343 */
			reg = < 0x40005c00 0x400 >;                  /* in zephyr/dts/arm/st/f4/stm32f4.dtsi:344 */
			clocks = < &rcc 0x40 0x800000 >;             /* in zephyr/dts/arm/st/f4/stm32f4.dtsi:345 */
			interrupts = < 0x48 0x0 >,
			             < 0x49 0x0 >;                   /* in zephyr/dts/arm/st/f4/stm32f4.dtsi:346 */
			interrupt-names = "event",
			                  "error";                   /* in zephyr/dts/arm/st/f4/stm32f4.dtsi:347 */
			pinctrl-0 = < &i2c3_scl_pa8 &i2c3_sda_pb4 >; /* in joint_microros_tmc2209_gripper_as5600/boards/blackpill_f411ce.overlay:47 */
			pinctrl-names = "default";                   /* in joint_microros_tmc2209_gripper_as5600/boards/blackpill_f411ce.overlay:48 */
			status = "okay";                             /* in joint_microros_tmc2209_gripper_as5600/boards/blackpill_f411ce.overlay:49 */
			clock-frequency = < 0x186a0 >;               /* in joint_microros_tmc2209_gripper_as5600/boards/blackpill_f411ce.overlay:50 */
			phandle = < 0x21 >;                          /* in zephyr/dts/arm/st/f4/stm32f4.dtsi:721 */

			/* node '/soc/i2c@40005c00/as5600@36' defined in joint_microros_tmc2209_gripper_as5600/boards/blackpill_f411ce.overlay:52 */
			as5600_3: as5600@36 {
				compatible = "ams,as5600"; /* in joint_microros_tmc2209_gripper_as5600/boards/blackpill_f411ce.overlay:53 */
				status = "okay";           /* in joint_microros_tmc2209_gripper_as5600/boards/blackpill_f411ce.overlay:54 */
				reg = < 0x36 >;            /* in joint_microros_tmc2209_gripper_as5600/boards/blackpill_f411ce.overlay:55 */
			};
		};

		/* node '/soc/spi@40013000' defined in zephyr/dts/arm/st/f4/stm32f4.dtsi:351 */
		spi1: spi@40013000 {
			compatible = "st,stm32-spi";                                               /* in zephyr/dts/arm/st/f4/stm32f4.dtsi:352 */
			#address-cells = < 0x1 >;                                                  /* in zephyr/dts/arm/st/f4/stm32f4.dtsi:353 */
			#size-cells = < 0x0 >;                                                     /* in zephyr/dts/arm/st/f4/stm32f4.dtsi:354 */
			reg = < 0x40013000 0x400 >;                                                /* in zephyr/dts/arm/st/f4/stm32f4.dtsi:355 */
			clocks = < &rcc 0x44 0x1000 >;                                             /* in zephyr/dts/arm/st/f4/stm32f4.dtsi:356 */
			interrupts = < 0x23 0x5 >;                                                 /* in zephyr/dts/arm/st/f4/stm32f4.dtsi:357 */
			st,spi-data-width = "limited-8-16-bit";                                    /* in zephyr/dts/arm/st/f4/stm32f4.dtsi:358 */
			pinctrl-0 = < &spi1_sck_pa5 &spi1_nss_pa4 &spi1_miso_pa6 &spi1_mosi_pa7 >; /* in zephyr/boards/weact/blackpill_f411ce/blackpill_f411ce.dts:111 */
			pinctrl-names = "default";                                                 /* in zephyr/boards/weact/blackpill_f411ce/blackpill_f411ce.dts:113 */
			status = "okay";                                                           /* in zephyr/boards/weact/blackpill_f411ce/blackpill_f411ce.dts:114 */
		};

		/* node '/soc/usb@50000000' defined in zephyr/dts/arm/st/f4/stm32f4.dtsi:362 */
		usbotg_fs: zephyr_udc0: usb@50000000 {
			compatible = "st,stm32-otgfs";                           /* in zephyr/dts/arm/st/f4/stm32f4.dtsi:363 */
			reg = < 0x50000000 0x40000 >;                            /* in zephyr/dts/arm/st/f4/stm32f4.dtsi:364 */
			interrupts = < 0x43 0x0 >;                               /* in zephyr/dts/arm/st/f4/stm32f4.dtsi:365 */
			interrupt-names = "otgfs";                               /* in zephyr/dts/arm/st/f4/stm32f4.dtsi:366 */
			num-bidir-endpoints = < 0x4 >;                           /* in zephyr/dts/arm/st/f4/stm32f4.dtsi:367 */
			ram-size = < 0x500 >;                                    /* in zephyr/dts/arm/st/f4/stm32f4.dtsi:368 */
			maximum-speed = "full-speed";                            /* in zephyr/dts/arm/st/f4/stm32f4.dtsi:369 */
			phys = < &otgfs_phy >;                                   /* in zephyr/dts/arm/st/f4/stm32f4.dtsi:370 */
			clocks = < &rcc 0x34 0x80 >,
			         < &rcc 0x7 0xff >;                              /* in zephyr/dts/arm/st/f4/stm32f4.dtsi:371 */
			pinctrl-0 = < &usb_otg_fs_dm_pa11 &usb_otg_fs_dp_pa12 >; /* in joint_microros_tmc2209_gripper_as5600/boards/blackpill_f411ce.overlay:145 */
			pinctrl-names = "default";                               /* in joint_microros_tmc2209_gripper_as5600/boards/blackpill_f411ce.overlay:146 */
			status = "okay";                                         /* in joint_microros_tmc2209_gripper_as5600/boards/blackpill_f411ce.overlay:147 */

			/* node '/soc/usb@50000000/cdc_acm_uart0' defined in joint_microros_tmc2209_gripper_as5600/boards/blackpill_f411ce.overlay:151 */
			cdc_acm_uart0: cdc_acm_uart0 {
				compatible = "zephyr,cdc-acm-uart"; /* in joint_microros_tmc2209_gripper_as5600/boards/blackpill_f411ce.overlay:152 */
				label = "CDC_ACM_0";                /* in joint_microros_tmc2209_gripper_as5600/boards/blackpill_f411ce.overlay:153 */
			};
		};

		/* node '/soc/timers@40010000' defined in zephyr/dts/arm/st/f4/stm32f4.dtsi:376 */
		timers1: timers@40010000 {
			compatible = "st,stm32-timers"; /* in zephyr/dts/arm/st/f4/stm32f4.dtsi:377 */
			reg = < 0x40010000 0x400 >;     /* in zephyr/dts/arm/st/f4/stm32f4.dtsi:378 */
			clocks = < &rcc 0x44 0x1 >,
			         < &rcc 0x16 0xff >;    /* in zephyr/dts/arm/st/f4/stm32f4.dtsi:379 */
			resets = < &rctl 0x480 >;       /* in zephyr/dts/arm/st/f4/stm32f4.dtsi:381 */
			interrupts = < 0x18 0x0 >,
			             < 0x19 0x0 >,
			             < 0x1a 0x0 >,
			             < 0x1b 0x0 >;      /* in zephyr/dts/arm/st/f4/stm32f4.dtsi:382 */
			interrupt-names = "brk",
			                  "up",
			                  "trgcom",
			                  "cc";         /* in zephyr/dts/arm/st/f4/stm32f4.dtsi:383 */
			st,prescaler = < 0x0 >;         /* in zephyr/dts/arm/st/f4/stm32f4.dtsi:384 */
			status = "disabled";            /* in zephyr/dts/arm/st/f4/stm32f4.dtsi:385 */

			/* node '/soc/timers@40010000/pwm' defined in zephyr/dts/arm/st/f4/stm32f4.dtsi:387 */
			pwm {
				compatible = "st,stm32-pwm"; /* in zephyr/dts/arm/st/f4/stm32f4.dtsi:388 */
				status = "disabled";         /* in zephyr/dts/arm/st/f4/stm32f4.dtsi:389 */
				#pwm-cells = < 0x3 >;        /* in zephyr/dts/arm/st/f4/stm32f4.dtsi:390 */
			};

			/* node '/soc/timers@40010000/counter' defined in zephyr/dts/arm/st/f4/stm32f4.dtsi:393 */
			counter {
				compatible = "st,stm32-counter"; /* in zephyr/dts/arm/st/f4/stm32f4.dtsi:394 */
				status = "disabled";             /* in zephyr/dts/arm/st/f4/stm32f4.dtsi:395 */
			};

			/* node '/soc/timers@40010000/qdec' defined in zephyr/dts/arm/st/f4/stm32f4.dtsi:398 */
			qdec {
				compatible = "st,stm32-qdec";    /* in zephyr/dts/arm/st/f4/stm32f4.dtsi:399 */
				st,input-filter-level = < 0x0 >; /* in zephyr/dts/arm/st/f4/stm32f4.dtsi:400 */
				status = "disabled";             /* in zephyr/dts/arm/st/f4/stm32f4.dtsi:401 */
			};
		};

		/* node '/soc/timers@40000000' defined in zephyr/dts/arm/st/f4/stm32f4.dtsi:405 */
		timers2: timers@40000000 {
			compatible = "st,stm32-timers"; /* in zephyr/dts/arm/st/f4/stm32f4.dtsi:406 */
			reg = < 0x40000000 0x400 >;     /* in zephyr/dts/arm/st/f4/stm32f4.dtsi:407 */
			clocks = < &rcc 0x40 0x1 >,
			         < &rcc 0x15 0xff >;    /* in zephyr/dts/arm/st/f4/stm32f4.dtsi:408 */
			resets = < &rctl 0x400 >;       /* in zephyr/dts/arm/st/f4/stm32f4.dtsi:410 */
			interrupts = < 0x1c 0x0 >;      /* in zephyr/dts/arm/st/f4/stm32f4.dtsi:411 */
			interrupt-names = "global";     /* in zephyr/dts/arm/st/f4/stm32f4.dtsi:412 */
			st,prescaler = < 0x0 >;         /* in zephyr/dts/arm/st/f4/stm32f4.dtsi:413 */
			status = "disabled";            /* in zephyr/dts/arm/st/f4/stm32f4.dtsi:414 */

			/* node '/soc/timers@40000000/pwm' defined in zephyr/dts/arm/st/f4/stm32f4.dtsi:416 */
			pwm {
				compatible = "st,stm32-pwm"; /* in zephyr/dts/arm/st/f4/stm32f4.dtsi:417 */
				status = "disabled";         /* in zephyr/dts/arm/st/f4/stm32f4.dtsi:418 */
				#pwm-cells = < 0x3 >;        /* in zephyr/dts/arm/st/f4/stm32f4.dtsi:419 */
			};

			/* node '/soc/timers@40000000/counter' defined in zephyr/dts/arm/st/f4/stm32f4.dtsi:422 */
			counter {
				compatible = "st,stm32-counter"; /* in zephyr/dts/arm/st/f4/stm32f4.dtsi:423 */
				status = "disabled";             /* in zephyr/dts/arm/st/f4/stm32f4.dtsi:424 */
			};

			/* node '/soc/timers@40000000/qdec' defined in zephyr/dts/arm/st/f4/stm32f4.dtsi:427 */
			qdec {
				compatible = "st,stm32-qdec";    /* in zephyr/dts/arm/st/f4/stm32f4.dtsi:428 */
				st,input-filter-level = < 0x0 >; /* in zephyr/dts/arm/st/f4/stm32f4.dtsi:429 */
				status = "disabled";             /* in zephyr/dts/arm/st/f4/stm32f4.dtsi:430 */
			};
		};

		/* node '/soc/timers@40000400' defined in zephyr/dts/arm/st/f4/stm32f4.dtsi:434 */
		timers3: timers@40000400 {
			compatible = "st,stm32-timers"; /* in zephyr/dts/arm/st/f4/stm32f4.dtsi:435 */
			reg = < 0x40000400 0x400 >;     /* in zephyr/dts/arm/st/f4/stm32f4.dtsi:436 */
			clocks = < &rcc 0x40 0x2 >,
			         < &rcc 0x15 0xff >;    /* in zephyr/dts/arm/st/f4/stm32f4.dtsi:437 */
			resets = < &rctl 0x401 >;       /* in zephyr/dts/arm/st/f4/stm32f4.dtsi:439 */
			interrupts = < 0x1d 0x0 >;      /* in zephyr/dts/arm/st/f4/stm32f4.dtsi:440 */
			interrupt-names = "global";     /* in zephyr/dts/arm/st/f4/stm32f4.dtsi:441 */
			st,prescaler = < 0x0 >;         /* in zephyr/dts/arm/st/f4/stm32f4.dtsi:442 */
			status = "disabled";            /* in zephyr/dts/arm/st/f4/stm32f4.dtsi:443 */

			/* node '/soc/timers@40000400/pwm' defined in zephyr/dts/arm/st/f4/stm32f4.dtsi:445 */
			pwm {
				compatible = "st,stm32-pwm"; /* in zephyr/dts/arm/st/f4/stm32f4.dtsi:446 */
				status = "disabled";         /* in zephyr/dts/arm/st/f4/stm32f4.dtsi:447 */
				#pwm-cells = < 0x3 >;        /* in zephyr/dts/arm/st/f4/stm32f4.dtsi:448 */
			};

			/* node '/soc/timers@40000400/counter' defined in zephyr/dts/arm/st/f4/stm32f4.dtsi:451 */
			counter {
				compatible = "st,stm32-counter"; /* in zephyr/dts/arm/st/f4/stm32f4.dtsi:452 */
				status = "disabled";             /* in zephyr/dts/arm/st/f4/stm32f4.dtsi:453 */
			};

			/* node '/soc/timers@40000400/qdec' defined in zephyr/dts/arm/st/f4/stm32f4.dtsi:456 */
			qdec {
				compatible = "st,stm32-qdec";    /* in zephyr/dts/arm/st/f4/stm32f4.dtsi:457 */
				st,input-filter-level = < 0x0 >; /* in zephyr/dts/arm/st/f4/stm32f4.dtsi:458 */
				status = "disabled";             /* in zephyr/dts/arm/st/f4/stm32f4.dtsi:459 */
			};
		};

		/* node '/soc/timers@40000800' defined in zephyr/dts/arm/st/f4/stm32f4.dtsi:463 */
		timers4: timers@40000800 {
			compatible = "st,stm32-timers"; /* in zephyr/dts/arm/st/f4/stm32f4.dtsi:464 */
			reg = < 0x40000800 0x400 >;     /* in zephyr/dts/arm/st/f4/stm32f4.dtsi:465 */
			clocks = < &rcc 0x40 0x4 >,
			         < &rcc 0x15 0xff >;    /* in zephyr/dts/arm/st/f4/stm32f4.dtsi:466 */
			resets = < &rctl 0x402 >;       /* in zephyr/dts/arm/st/f4/stm32f4.dtsi:468 */
			interrupts = < 0x1e 0x0 >;      /* in zephyr/dts/arm/st/f4/stm32f4.dtsi:469 */
			interrupt-names = "global";     /* in zephyr/dts/arm/st/f4/stm32f4.dtsi:470 */
			status = "okay";                /* in joint_microros_tmc2209_gripper_as5600/boards/blackpill_f411ce.overlay:68 */
			st,prescaler = < 0x3e8 >;       /* in joint_microros_tmc2209_gripper_as5600/boards/blackpill_f411ce.overlay:69 */

			/* node '/soc/timers@40000800/pwm' defined in zephyr/dts/arm/st/f4/stm32f4.dtsi:474 */
			pwm4: pwm {
				compatible = "st,stm32-pwm";   /* in zephyr/dts/arm/st/f4/stm32f4.dtsi:475 */
				#pwm-cells = < 0x3 >;          /* in zephyr/dts/arm/st/f4/stm32f4.dtsi:477 */
				status = "okay";               /* in joint_microros_tmc2209_gripper_as5600/boards/blackpill_f411ce.overlay:72 */
				pinctrl-0 = < &tim4_ch3_pb8 >; /* in joint_microros_tmc2209_gripper_as5600/boards/blackpill_f411ce.overlay:73 */
				pinctrl-names = "default";     /* in joint_microros_tmc2209_gripper_as5600/boards/blackpill_f411ce.overlay:74 */
				phandle = < 0x23 >;            /* in joint_microros_tmc2209_gripper_as5600/boards/blackpill_f411ce.overlay:89 */
			};

			/* node '/soc/timers@40000800/counter' defined in zephyr/dts/arm/st/f4/stm32f4.dtsi:480 */
			counter {
				compatible = "st,stm32-counter"; /* in zephyr/dts/arm/st/f4/stm32f4.dtsi:481 */
				status = "disabled";             /* in zephyr/dts/arm/st/f4/stm32f4.dtsi:482 */
			};

			/* node '/soc/timers@40000800/qdec' defined in zephyr/dts/arm/st/f4/stm32f4.dtsi:485 */
			qdec {
				compatible = "st,stm32-qdec";    /* in zephyr/dts/arm/st/f4/stm32f4.dtsi:486 */
				st,input-filter-level = < 0x0 >; /* in zephyr/dts/arm/st/f4/stm32f4.dtsi:487 */
				status = "disabled";             /* in zephyr/dts/arm/st/f4/stm32f4.dtsi:488 */
			};
		};

		/* node '/soc/timers@40000c00' defined in zephyr/dts/arm/st/f4/stm32f4.dtsi:492 */
		timers5: timers@40000c00 {
			compatible = "st,stm32-timers"; /* in zephyr/dts/arm/st/f4/stm32f4.dtsi:493 */
			reg = < 0x40000c00 0x400 >;     /* in zephyr/dts/arm/st/f4/stm32f4.dtsi:494 */
			clocks = < &rcc 0x40 0x8 >,
			         < &rcc 0x15 0xff >;    /* in zephyr/dts/arm/st/f4/stm32f4.dtsi:495 */
			resets = < &rctl 0x403 >;       /* in zephyr/dts/arm/st/f4/stm32f4.dtsi:497 */
			interrupts = < 0x32 0x0 >;      /* in zephyr/dts/arm/st/f4/stm32f4.dtsi:498 */
			interrupt-names = "global";     /* in zephyr/dts/arm/st/f4/stm32f4.dtsi:499 */
			st,prescaler = < 0x0 >;         /* in zephyr/dts/arm/st/f4/stm32f4.dtsi:500 */
			status = "disabled";            /* in zephyr/dts/arm/st/f4/stm32f4.dtsi:501 */

			/* node '/soc/timers@40000c00/pwm' defined in zephyr/dts/arm/st/f4/stm32f4.dtsi:503 */
			pwm {
				compatible = "st,stm32-pwm"; /* in zephyr/dts/arm/st/f4/stm32f4.dtsi:504 */
				status = "disabled";         /* in zephyr/dts/arm/st/f4/stm32f4.dtsi:505 */
				#pwm-cells = < 0x3 >;        /* in zephyr/dts/arm/st/f4/stm32f4.dtsi:506 */
			};

			/* node '/soc/timers@40000c00/counter' defined in zephyr/dts/arm/st/f4/stm32f4.dtsi:509 */
			counter {
				compatible = "st,stm32-counter"; /* in zephyr/dts/arm/st/f4/stm32f4.dtsi:510 */
				status = "disabled";             /* in zephyr/dts/arm/st/f4/stm32f4.dtsi:511 */
			};

			/* node '/soc/timers@40000c00/qdec' defined in zephyr/dts/arm/st/f4/stm32f4.dtsi:514 */
			qdec {
				compatible = "st,stm32-qdec";    /* in zephyr/dts/arm/st/f4/stm32f4.dtsi:515 */
				st,input-filter-level = < 0x0 >; /* in zephyr/dts/arm/st/f4/stm32f4.dtsi:516 */
				status = "disabled";             /* in zephyr/dts/arm/st/f4/stm32f4.dtsi:517 */
			};
		};

		/* node '/soc/timers@40014000' defined in zephyr/dts/arm/st/f4/stm32f4.dtsi:521 */
		timers9: timers@40014000 {
			compatible = "st,stm32-timers"; /* in zephyr/dts/arm/st/f4/stm32f4.dtsi:522 */
			reg = < 0x40014000 0x400 >;     /* in zephyr/dts/arm/st/f4/stm32f4.dtsi:523 */
			clocks = < &rcc 0x44 0x10000 >,
			         < &rcc 0x16 0xff >;    /* in zephyr/dts/arm/st/f4/stm32f4.dtsi:524 */
			resets = < &rctl 0x490 >;       /* in zephyr/dts/arm/st/f4/stm32f4.dtsi:526 */
			interrupts = < 0x18 0x0 >;      /* in zephyr/dts/arm/st/f4/stm32f4.dtsi:527 */
			interrupt-names = "global";     /* in zephyr/dts/arm/st/f4/stm32f4.dtsi:528 */
			st,prescaler = < 0x0 >;         /* in zephyr/dts/arm/st/f4/stm32f4.dtsi:529 */
			status = "disabled";            /* in zephyr/dts/arm/st/f4/stm32f4.dtsi:530 */

			/* node '/soc/timers@40014000/pwm' defined in zephyr/dts/arm/st/f4/stm32f4.dtsi:532 */
			pwm {
				compatible = "st,stm32-pwm"; /* in zephyr/dts/arm/st/f4/stm32f4.dtsi:533 */
				status = "disabled";         /* in zephyr/dts/arm/st/f4/stm32f4.dtsi:534 */
				#pwm-cells = < 0x3 >;        /* in zephyr/dts/arm/st/f4/stm32f4.dtsi:535 */
			};

			/* node '/soc/timers@40014000/counter' defined in zephyr/dts/arm/st/f4/stm32f4.dtsi:538 */
			counter {
				compatible = "st,stm32-counter"; /* in zephyr/dts/arm/st/f4/stm32f4.dtsi:539 */
				status = "disabled";             /* in zephyr/dts/arm/st/f4/stm32f4.dtsi:540 */
			};
		};

		/* node '/soc/timers@40014400' defined in zephyr/dts/arm/st/f4/stm32f4.dtsi:544 */
		timers10: timers@40014400 {
			compatible = "st,stm32-timers"; /* in zephyr/dts/arm/st/f4/stm32f4.dtsi:545 */
			reg = < 0x40014400 0x400 >;     /* in zephyr/dts/arm/st/f4/stm32f4.dtsi:546 */
			clocks = < &rcc 0x44 0x20000 >,
			         < &rcc 0x16 0xff >;    /* in zephyr/dts/arm/st/f4/stm32f4.dtsi:547 */
			resets = < &rctl 0x491 >;       /* in zephyr/dts/arm/st/f4/stm32f4.dtsi:549 */
			interrupts = < 0x19 0x0 >;      /* in zephyr/dts/arm/st/f4/stm32f4.dtsi:550 */
			interrupt-names = "global";     /* in zephyr/dts/arm/st/f4/stm32f4.dtsi:551 */
			st,prescaler = < 0x0 >;         /* in zephyr/dts/arm/st/f4/stm32f4.dtsi:552 */
			status = "disabled";            /* in zephyr/dts/arm/st/f4/stm32f4.dtsi:553 */

			/* node '/soc/timers@40014400/pwm' defined in zephyr/dts/arm/st/f4/stm32f4.dtsi:555 */
			pwm {
				compatible = "st,stm32-pwm"; /* in zephyr/dts/arm/st/f4/stm32f4.dtsi:556 */
				status = "disabled";         /* in zephyr/dts/arm/st/f4/stm32f4.dtsi:557 */
				#pwm-cells = < 0x3 >;        /* in zephyr/dts/arm/st/f4/stm32f4.dtsi:558 */
			};

			/* node '/soc/timers@40014400/counter' defined in zephyr/dts/arm/st/f4/stm32f4.dtsi:561 */
			counter {
				compatible = "st,stm32-counter"; /* in zephyr/dts/arm/st/f4/stm32f4.dtsi:562 */
				status = "disabled";             /* in zephyr/dts/arm/st/f4/stm32f4.dtsi:563 */
			};
		};

		/* node '/soc/timers@40014800' defined in zephyr/dts/arm/st/f4/stm32f4.dtsi:567 */
		timers11: timers@40014800 {
			compatible = "st,stm32-timers"; /* in zephyr/dts/arm/st/f4/stm32f4.dtsi:568 */
			reg = < 0x40014800 0x400 >;     /* in zephyr/dts/arm/st/f4/stm32f4.dtsi:569 */
			clocks = < &rcc 0x44 0x40000 >,
			         < &rcc 0x16 0xff >;    /* in zephyr/dts/arm/st/f4/stm32f4.dtsi:570 */
			resets = < &rctl 0x492 >;       /* in zephyr/dts/arm/st/f4/stm32f4.dtsi:572 */
			interrupts = < 0x1a 0x0 >;      /* in zephyr/dts/arm/st/f4/stm32f4.dtsi:573 */
			interrupt-names = "global";     /* in zephyr/dts/arm/st/f4/stm32f4.dtsi:574 */
			st,prescaler = < 0x0 >;         /* in zephyr/dts/arm/st/f4/stm32f4.dtsi:575 */
			status = "disabled";            /* in zephyr/dts/arm/st/f4/stm32f4.dtsi:576 */

			/* node '/soc/timers@40014800/pwm' defined in zephyr/dts/arm/st/f4/stm32f4.dtsi:578 */
			pwm {
				compatible = "st,stm32-pwm"; /* in zephyr/dts/arm/st/f4/stm32f4.dtsi:579 */
				status = "disabled";         /* in zephyr/dts/arm/st/f4/stm32f4.dtsi:580 */
				#pwm-cells = < 0x3 >;        /* in zephyr/dts/arm/st/f4/stm32f4.dtsi:581 */
			};

			/* node '/soc/timers@40014800/counter' defined in zephyr/dts/arm/st/f4/stm32f4.dtsi:584 */
			counter {
				compatible = "st,stm32-counter"; /* in zephyr/dts/arm/st/f4/stm32f4.dtsi:585 */
				status = "disabled";             /* in zephyr/dts/arm/st/f4/stm32f4.dtsi:586 */
			};
		};

		/* node '/soc/rtc@40002800' defined in zephyr/dts/arm/st/f4/stm32f4.dtsi:590 */
		rtc: rtc@40002800 {
			compatible = "st,stm32-rtc";       /* in zephyr/dts/arm/st/f4/stm32f4.dtsi:591 */
			reg = < 0x40002800 0x400 >;        /* in zephyr/dts/arm/st/f4/stm32f4.dtsi:592 */
			interrupts = < 0x29 0x0 >;         /* in zephyr/dts/arm/st/f4/stm32f4.dtsi:593 */
			prescaler = < 0x8000 >;            /* in zephyr/dts/arm/st/f4/stm32f4.dtsi:595 */
			alarms-count = < 0x2 >;            /* in zephyr/dts/arm/st/f4/stm32f4.dtsi:596 */
			alrm-exti-line = < 0x11 >;         /* in zephyr/dts/arm/st/f4/stm32f4.dtsi:597 */
			clocks = < &rcc 0x40 0x10000000 >,
			         < &rcc 0x3 0x2280070 >;   /* in zephyr/boards/weact/blackpill_f411ce/blackpill_f411ce.dts:118 */
			status = "okay";                   /* in zephyr/boards/weact/blackpill_f411ce/blackpill_f411ce.dts:120 */

			/* node '/soc/rtc@40002800/backup_regs' defined in zephyr/dts/arm/st/f4/stm32f4.dtsi:600 */
			bbram: backup_regs {
				compatible = "st,stm32-bbram"; /* in zephyr/dts/arm/st/f4/stm32f4.dtsi:601 */
				st,backup-regs = < 0x14 >;     /* in zephyr/dts/arm/st/f4/stm32f4.dtsi:602 */
				status = "disabled";           /* in zephyr/dts/arm/st/f4/stm32f4.dtsi:603 */
			};
		};

		/* node '/soc/adc@40012000' defined in zephyr/dts/arm/st/f4/stm32f4.dtsi:607 */
		adc1: adc@40012000 {
			compatible = "st,stm32f4-adc",
			             "st,stm32-adc";                                 /* in zephyr/dts/arm/st/f4/stm32f4.dtsi:608 */
			reg = < 0x40012000 0x400 >;                                  /* in zephyr/dts/arm/st/f4/stm32f4.dtsi:609 */
			clocks = < &rcc 0x44 0x100 >;                                /* in zephyr/dts/arm/st/f4/stm32f4.dtsi:610 */
			clock-names = "adcx";                                        /* in zephyr/dts/arm/st/f4/stm32f4.dtsi:611 */
			interrupts = < 0x12 0x0 >;                                   /* in zephyr/dts/arm/st/f4/stm32f4.dtsi:612 */
			#io-channel-cells = < 0x1 >;                                 /* in zephyr/dts/arm/st/f4/stm32f4.dtsi:613 */
			st,adc-resolutions = < 0xc 0xa 0x8 0x6 >;                    /* in zephyr/dts/arm/st/f4/stm32f4.dtsi:614 */
			sampling-times = < 0x3 0xf 0x1c 0x38 0x54 0x70 0x90 0x1e0 >; /* in zephyr/dts/arm/st/f4/stm32f4.dtsi:615 */
			st,adc-sequencer = "programmable";                           /* in zephyr/dts/arm/st/f4/stm32f4.dtsi:617 */
			st,adc-oversampler = "none";                                 /* in zephyr/dts/arm/st/f4/stm32f4.dtsi:618 */
			st,adc-internal-regulator = "none";                          /* in zephyr/dts/arm/st/f4/stm32f4.dtsi:619 */
			st,adc-has-injected-support;                                 /* in zephyr/dts/arm/st/f4/stm32f4.dtsi:620 */
			pinctrl-0 = < &adc1_in1_pa1 >;                               /* in zephyr/boards/weact/blackpill_f411ce/blackpill_f411ce.dts:130 */
			pinctrl-names = "default";                                   /* in zephyr/boards/weact/blackpill_f411ce/blackpill_f411ce.dts:131 */
			st,adc-clock-source = "SYNC";                                /* in zephyr/boards/weact/blackpill_f411ce/blackpill_f411ce.dts:132 */
			st,adc-prescaler = < 0x2 >;                                  /* in zephyr/boards/weact/blackpill_f411ce/blackpill_f411ce.dts:133 */
			status = "okay";                                             /* in zephyr/boards/weact/blackpill_f411ce/blackpill_f411ce.dts:134 */
			phandle = < 0x1d >;                                          /* in zephyr/dts/arm/st/f4/stm32f411.dtsi:65 */
		};

		/* node '/soc/dma@40026000' defined in zephyr/dts/arm/st/f4/stm32f4.dtsi:624 */
		dma1: dma@40026000 {
			compatible = "st,stm32-dma-v1";                                                      /* in zephyr/dts/arm/st/f4/stm32f4.dtsi:625 */
			#dma-cells = < 0x4 >;                                                                /* in zephyr/dts/arm/st/f4/stm32f4.dtsi:626 */
			reg = < 0x40026000 0x400 >;                                                          /* in zephyr/dts/arm/st/f4/stm32f4.dtsi:627 */
			interrupts = < 0xb 0x0 0xc 0x0 0xd 0x0 0xe 0x0 0xf 0x0 0x10 0x0 0x11 0x0 0x2f 0x0 >; /* in zephyr/dts/arm/st/f4/stm32f4.dtsi:628 */
			clocks = < &rcc 0x30 0x200000 >;                                                     /* in zephyr/dts/arm/st/f4/stm32f4.dtsi:629 */
			status = "disabled";                                                                 /* in zephyr/dts/arm/st/f4/stm32f4.dtsi:630 */
			phandle = < 0x16 >;                                                                  /* in zephyr/dts/arm/st/f4/stm32f401.dtsi:61 */
		};

		/* node '/soc/dma@40026400' defined in zephyr/dts/arm/st/f4/stm32f4.dtsi:633 */
		dma2: dma@40026400 {
			compatible = "st,stm32-dma-v1";                                                           /* in zephyr/dts/arm/st/f4/stm32f4.dtsi:634 */
			#dma-cells = < 0x4 >;                                                                     /* in zephyr/dts/arm/st/f4/stm32f4.dtsi:635 */
			reg = < 0x40026400 0x400 >;                                                               /* in zephyr/dts/arm/st/f4/stm32f4.dtsi:636 */
			interrupts = < 0x38 0x0 0x39 0x0 0x3a 0x0 0x3b 0x0 0x3c 0x0 0x44 0x0 0x45 0x0 0x46 0x0 >; /* in zephyr/dts/arm/st/f4/stm32f4.dtsi:637 */
			clocks = < &rcc 0x30 0x400000 >;                                                          /* in zephyr/dts/arm/st/f4/stm32f4.dtsi:638 */
			st,mem2mem;                                                                               /* in zephyr/dts/arm/st/f4/stm32f4.dtsi:639 */
			status = "disabled";                                                                      /* in zephyr/dts/arm/st/f4/stm32f4.dtsi:640 */
			phandle = < 0x17 >;                                                                       /* in zephyr/dts/arm/st/f4/stm32f411.dtsi:31 */
		};

		/* node '/soc/sdmmc@40012c00' defined in zephyr/dts/arm/st/f4/stm32f4.dtsi:643 */
		sdmmc1: sdmmc@40012c00 {
			compatible = "st,stm32-sdmmc"; /* in zephyr/dts/arm/st/f4/stm32f4.dtsi:644 */
			reg = < 0x40012c00 0x400 >;    /* in zephyr/dts/arm/st/f4/stm32f4.dtsi:645 */
			clocks = < &rcc 0x44 0x800 >,
			         < &rcc 0x7 0xff >;    /* in zephyr/dts/arm/st/f4/stm32f4.dtsi:646 */
			resets = < &rctl 0x48b >;      /* in zephyr/dts/arm/st/f4/stm32f4.dtsi:648 */
			interrupts = < 0x31 0x0 >;     /* in zephyr/dts/arm/st/f4/stm32f4.dtsi:649 */
			status = "disabled";           /* in zephyr/dts/arm/st/f4/stm32f4.dtsi:650 */
		};

		/* node '/soc/spi@40003800' defined in zephyr/dts/arm/st/f4/stm32f401.dtsi:21 */
		spi2: spi@40003800 {
			compatible = "st,stm32-spi";            /* in zephyr/dts/arm/st/f4/stm32f401.dtsi:22 */
			#address-cells = < 0x1 >;               /* in zephyr/dts/arm/st/f4/stm32f401.dtsi:23 */
			#size-cells = < 0x0 >;                  /* in zephyr/dts/arm/st/f4/stm32f401.dtsi:24 */
			reg = < 0x40003800 0x400 >;             /* in zephyr/dts/arm/st/f4/stm32f401.dtsi:25 */
			clocks = < &rcc 0x40 0x4000 >;          /* in zephyr/dts/arm/st/f4/stm32f401.dtsi:26 */
			interrupts = < 0x24 0x5 >;              /* in zephyr/dts/arm/st/f4/stm32f401.dtsi:27 */
			st,spi-data-width = "limited-8-16-bit"; /* in zephyr/dts/arm/st/f4/stm32f401.dtsi:28 */
			status = "disabled";                    /* in zephyr/dts/arm/st/f4/stm32f401.dtsi:29 */
		};

		/* node '/soc/spi@40003c00' defined in zephyr/dts/arm/st/f4/stm32f401.dtsi:32 */
		spi3: spi@40003c00 {
			compatible = "st,stm32-spi";            /* in zephyr/dts/arm/st/f4/stm32f401.dtsi:33 */
			#address-cells = < 0x1 >;               /* in zephyr/dts/arm/st/f4/stm32f401.dtsi:34 */
			#size-cells = < 0x0 >;                  /* in zephyr/dts/arm/st/f4/stm32f401.dtsi:35 */
			reg = < 0x40003c00 0x400 >;             /* in zephyr/dts/arm/st/f4/stm32f401.dtsi:36 */
			clocks = < &rcc 0x40 0x8000 >;          /* in zephyr/dts/arm/st/f4/stm32f401.dtsi:37 */
			interrupts = < 0x33 0x5 >;              /* in zephyr/dts/arm/st/f4/stm32f401.dtsi:38 */
			st,spi-data-width = "limited-8-16-bit"; /* in zephyr/dts/arm/st/f4/stm32f401.dtsi:39 */
			status = "disabled";                    /* in zephyr/dts/arm/st/f4/stm32f401.dtsi:40 */
		};

		/* node '/soc/spi@40013400' defined in zephyr/dts/arm/st/f4/stm32f401.dtsi:43 */
		spi4: spi@40013400 {
			compatible = "st,stm32-spi";            /* in zephyr/dts/arm/st/f4/stm32f401.dtsi:44 */
			#address-cells = < 0x1 >;               /* in zephyr/dts/arm/st/f4/stm32f401.dtsi:45 */
			#size-cells = < 0x0 >;                  /* in zephyr/dts/arm/st/f4/stm32f401.dtsi:46 */
			reg = < 0x40013400 0x400 >;             /* in zephyr/dts/arm/st/f4/stm32f401.dtsi:47 */
			clocks = < &rcc 0x44 0x2000 >;          /* in zephyr/dts/arm/st/f4/stm32f401.dtsi:48 */
			interrupts = < 0x54 0x5 >;              /* in zephyr/dts/arm/st/f4/stm32f401.dtsi:49 */
			st,spi-data-width = "limited-8-16-bit"; /* in zephyr/dts/arm/st/f4/stm32f401.dtsi:50 */
			status = "disabled";                    /* in zephyr/dts/arm/st/f4/stm32f401.dtsi:51 */
		};

		/* node '/soc/i2s@40003800' defined in zephyr/dts/arm/st/f4/stm32f401.dtsi:54 */
		i2s2: i2s@40003800 {
			compatible = "st,stm32-i2s";        /* in zephyr/dts/arm/st/f4/stm32f401.dtsi:55 */
			#address-cells = < 0x1 >;           /* in zephyr/dts/arm/st/f4/stm32f401.dtsi:56 */
			#size-cells = < 0x0 >;              /* in zephyr/dts/arm/st/f4/stm32f401.dtsi:57 */
			reg = < 0x40003800 0x400 >;         /* in zephyr/dts/arm/st/f4/stm32f401.dtsi:58 */
			clocks = < &rcc 0x40 0x4000 >;      /* in zephyr/dts/arm/st/f4/stm32f401.dtsi:59 */
			interrupts = < 0x24 0x5 >;          /* in zephyr/dts/arm/st/f4/stm32f401.dtsi:60 */
			dmas = < &dma1 0x4 0x0 0x400 0x3 >,
			       < &dma1 0x3 0x0 0x400 0x3 >; /* in zephyr/dts/arm/st/f4/stm32f401.dtsi:61 */
			dma-names = "tx",
			            "rx";                   /* in zephyr/dts/arm/st/f4/stm32f401.dtsi:63 */
			status = "disabled";                /* in zephyr/dts/arm/st/f4/stm32f401.dtsi:64 */
		};

		/* node '/soc/i2s@40003c00' defined in zephyr/dts/arm/st/f4/stm32f401.dtsi:67 */
		i2s3: i2s@40003c00 {
			compatible = "st,stm32-i2s";        /* in zephyr/dts/arm/st/f4/stm32f401.dtsi:68 */
			#address-cells = < 0x1 >;           /* in zephyr/dts/arm/st/f4/stm32f401.dtsi:69 */
			#size-cells = < 0x0 >;              /* in zephyr/dts/arm/st/f4/stm32f401.dtsi:70 */
			reg = < 0x40003c00 0x400 >;         /* in zephyr/dts/arm/st/f4/stm32f401.dtsi:71 */
			clocks = < &rcc 0x40 0x8000 >;      /* in zephyr/dts/arm/st/f4/stm32f401.dtsi:72 */
			interrupts = < 0x33 0x5 >;          /* in zephyr/dts/arm/st/f4/stm32f401.dtsi:73 */
			dmas = < &dma1 0x5 0x0 0x400 0x3 >,
			       < &dma1 0x0 0x0 0x400 0x3 >; /* in zephyr/dts/arm/st/f4/stm32f401.dtsi:74 */
			dma-names = "tx",
			            "rx";                   /* in zephyr/dts/arm/st/f4/stm32f401.dtsi:76 */
			status = "disabled";                /* in zephyr/dts/arm/st/f4/stm32f401.dtsi:77 */
		};

		/* node '/soc/spi@40015000' defined in zephyr/dts/arm/st/f4/stm32f411.dtsi:13 */
		spi5: spi@40015000 {
			compatible = "st,stm32-spi";            /* in zephyr/dts/arm/st/f4/stm32f411.dtsi:14 */
			#address-cells = < 0x1 >;               /* in zephyr/dts/arm/st/f4/stm32f411.dtsi:15 */
			#size-cells = < 0x0 >;                  /* in zephyr/dts/arm/st/f4/stm32f411.dtsi:16 */
			reg = < 0x40015000 0x400 >;             /* in zephyr/dts/arm/st/f4/stm32f411.dtsi:17 */
			clocks = < &rcc 0x44 0x100000 >;        /* in zephyr/dts/arm/st/f4/stm32f411.dtsi:18 */
			interrupts = < 0x55 0x5 >;              /* in zephyr/dts/arm/st/f4/stm32f411.dtsi:19 */
			st,spi-data-width = "limited-8-16-bit"; /* in zephyr/dts/arm/st/f4/stm32f411.dtsi:20 */
			status = "disabled";                    /* in zephyr/dts/arm/st/f4/stm32f411.dtsi:21 */
		};

		/* node '/soc/i2s@40013000' defined in zephyr/dts/arm/st/f4/stm32f411.dtsi:24 */
		i2s1: i2s@40013000 {
			compatible = "st,stm32-i2s";        /* in zephyr/dts/arm/st/f4/stm32f411.dtsi:25 */
			#address-cells = < 0x1 >;           /* in zephyr/dts/arm/st/f4/stm32f411.dtsi:26 */
			#size-cells = < 0x0 >;              /* in zephyr/dts/arm/st/f4/stm32f411.dtsi:27 */
			reg = < 0x40013000 0x400 >;         /* in zephyr/dts/arm/st/f4/stm32f411.dtsi:28 */
			clocks = < &rcc 0x44 0x1000 >;      /* in zephyr/dts/arm/st/f4/stm32f411.dtsi:29 */
			interrupts = < 0x23 0x5 >;          /* in zephyr/dts/arm/st/f4/stm32f411.dtsi:30 */
			dmas = < &dma2 0x3 0x3 0x400 0x3 >,
			       < &dma2 0x2 0x3 0x400 0x3 >; /* in zephyr/dts/arm/st/f4/stm32f411.dtsi:31 */
			dma-names = "tx",
			            "rx";                   /* in zephyr/dts/arm/st/f4/stm32f411.dtsi:33 */
			status = "disabled";                /* in zephyr/dts/arm/st/f4/stm32f411.dtsi:34 */
		};

		/* node '/soc/i2s@40013400' defined in zephyr/dts/arm/st/f4/stm32f411.dtsi:37 */
		i2s4: i2s@40013400 {
			compatible = "st,stm32-i2s";        /* in zephyr/dts/arm/st/f4/stm32f411.dtsi:38 */
			#address-cells = < 0x1 >;           /* in zephyr/dts/arm/st/f4/stm32f411.dtsi:39 */
			#size-cells = < 0x0 >;              /* in zephyr/dts/arm/st/f4/stm32f411.dtsi:40 */
			reg = < 0x40013400 0x400 >;         /* in zephyr/dts/arm/st/f4/stm32f411.dtsi:41 */
			clocks = < &rcc 0x44 0x2000 >;      /* in zephyr/dts/arm/st/f4/stm32f411.dtsi:42 */
			interrupts = < 0x54 0x5 >;          /* in zephyr/dts/arm/st/f4/stm32f411.dtsi:43 */
			dmas = < &dma2 0x1 0x4 0x400 0x3 >,
			       < &dma2 0x0 0x4 0x400 0x3 >; /* in zephyr/dts/arm/st/f4/stm32f411.dtsi:44 */
			dma-names = "tx",
			            "rx";                   /* in zephyr/dts/arm/st/f4/stm32f411.dtsi:46 */
			status = "disabled";                /* in zephyr/dts/arm/st/f4/stm32f411.dtsi:47 */
		};

		/* node '/soc/i2s@40015000' defined in zephyr/dts/arm/st/f4/stm32f411.dtsi:50 */
		i2s5: i2s@40015000 {
			compatible = "st,stm32-i2s";        /* in zephyr/dts/arm/st/f4/stm32f411.dtsi:51 */
			#address-cells = < 0x1 >;           /* in zephyr/dts/arm/st/f4/stm32f411.dtsi:52 */
			#size-cells = < 0x0 >;              /* in zephyr/dts/arm/st/f4/stm32f411.dtsi:53 */
			reg = < 0x40015000 0x400 >;         /* in zephyr/dts/arm/st/f4/stm32f411.dtsi:54 */
			clocks = < &rcc 0x44 0x100000 >;    /* in zephyr/dts/arm/st/f4/stm32f411.dtsi:55 */
			interrupts = < 0x55 0x5 >;          /* in zephyr/dts/arm/st/f4/stm32f411.dtsi:56 */
			dmas = < &dma2 0x6 0x7 0x400 0x3 >,
			       < &dma2 0x5 0x7 0x400 0x3 >; /* in zephyr/dts/arm/st/f4/stm32f411.dtsi:57 */
			dma-names = "tx",
			            "rx";                   /* in zephyr/dts/arm/st/f4/stm32f411.dtsi:59 */
			status = "disabled";                /* in zephyr/dts/arm/st/f4/stm32f411.dtsi:60 */
		};
	};

	/* node '/cpus' defined in zephyr/dts/arm/st/f4/stm32f4.dtsi:30 */
	cpus {
		#address-cells = < 0x1 >; /* in zephyr/dts/arm/st/f4/stm32f4.dtsi:31 */
		#size-cells = < 0x0 >;    /* in zephyr/dts/arm/st/f4/stm32f4.dtsi:32 */

		/* node '/cpus/cpu@0' defined in zephyr/dts/arm/st/f4/stm32f4.dtsi:34 */
		cpu0: cpu@0 {
			device_type = "cpu";           /* in zephyr/dts/arm/st/f4/stm32f4.dtsi:35 */
			compatible = "arm,cortex-m4f"; /* in zephyr/dts/arm/st/f4/stm32f4.dtsi:36 */
			reg = < 0x0 >;                 /* in zephyr/dts/arm/st/f4/stm32f4.dtsi:37 */
			cpu-power-states = < &stop >;  /* in zephyr/dts/arm/st/f4/stm32f4.dtsi:38 */
		};

		/* node '/cpus/power-states' defined in zephyr/dts/arm/st/f4/stm32f4.dtsi:41 */
		power-states {

			/* node '/cpus/power-states/stop' defined in zephyr/dts/arm/st/f4/stm32f4.dtsi:42 */
			stop: stop {
				compatible = "zephyr,power-state";    /* in zephyr/dts/arm/st/f4/stm32f4.dtsi:43 */
				power-state-name = "suspend-to-idle"; /* in zephyr/dts/arm/st/f4/stm32f4.dtsi:44 */
				min-residency-us = < 0x190 >;         /* in zephyr/dts/arm/st/f4/stm32f4.dtsi:51 */
				exit-latency-us = < 0x12c >;          /* in zephyr/dts/arm/st/f4/stm32f4.dtsi:52 */
				phandle = < 0x18 >;                   /* in zephyr/dts/arm/st/f4/stm32f4.dtsi:38 */
			};
		};
	};

	/* node '/memory@20000000' defined in zephyr/dts/arm/st/f4/stm32f4.dtsi:57 */
	sram0: memory@20000000 {
		compatible = "zephyr,memory-region",
		             "mmio-sram";            /* in zephyr/dts/arm/st/f4/stm32f4.dtsi:58 */
		zephyr,memory-region = "SRAM0";      /* in zephyr/dts/arm/st/f4/stm32f4.dtsi:59 */
		reg = < 0x20000000 0x20000 >;        /* in zephyr/dts/arm/st/f4/stm32f411Xe.dtsi:11 */
	};

	/* node '/clocks' defined in zephyr/dts/arm/st/f4/stm32f4.dtsi:62 */
	clocks {

		/* node '/clocks/clk-hse' defined in zephyr/dts/arm/st/f4/stm32f4.dtsi:63 */
		clk_hse: clk-hse {
			#clock-cells = < 0x0 >;            /* in zephyr/dts/arm/st/f4/stm32f4.dtsi:64 */
			compatible = "st,stm32-hse-clock"; /* in zephyr/dts/arm/st/f4/stm32f4.dtsi:65 */
			clock-frequency = < 0x17d7840 >;   /* in zephyr/boards/weact/blackpill_f411ce/blackpill_f411ce.dts:142 */
			status = "okay";                   /* in zephyr/boards/weact/blackpill_f411ce/blackpill_f411ce.dts:143 */
			phandle = < 0x19 >;                /* in zephyr/boards/weact/blackpill_f411ce/blackpill_f411ce.dts:151 */
		};

		/* node '/clocks/clk-hsi' defined in zephyr/dts/arm/st/f4/stm32f4.dtsi:69 */
		clk_hsi: clk-hsi {
			#clock-cells = < 0x0 >;         /* in zephyr/dts/arm/st/f4/stm32f4.dtsi:70 */
			compatible = "fixed-clock";     /* in zephyr/dts/arm/st/f4/stm32f4.dtsi:71 */
			clock-frequency = < 0xf42400 >; /* in zephyr/dts/arm/st/f4/stm32f4.dtsi:72 */
			status = "disabled";            /* in zephyr/dts/arm/st/f4/stm32f4.dtsi:73 */
		};

		/* node '/clocks/clk-lse' defined in zephyr/dts/arm/st/f4/stm32f4.dtsi:76 */
		clk_lse: clk-lse {
			#clock-cells = < 0x0 >;       /* in zephyr/dts/arm/st/f4/stm32f4.dtsi:77 */
			compatible = "fixed-clock";   /* in zephyr/dts/arm/st/f4/stm32f4.dtsi:78 */
			clock-frequency = < 0x8000 >; /* in zephyr/dts/arm/st/f4/stm32f4.dtsi:79 */
			status = "disabled";          /* in zephyr/dts/arm/st/f4/stm32f4.dtsi:80 */
		};

		/* node '/clocks/clk-lsi' defined in zephyr/dts/arm/st/f4/stm32f4.dtsi:83 */
		clk_lsi: clk-lsi {
			#clock-cells = < 0x0 >;       /* in zephyr/dts/arm/st/f4/stm32f4.dtsi:84 */
			compatible = "fixed-clock";   /* in zephyr/dts/arm/st/f4/stm32f4.dtsi:85 */
			clock-frequency = < 0x7d00 >; /* in zephyr/dts/arm/st/f4/stm32f4.dtsi:86 */
			status = "okay";              /* in zephyr/boards/weact/blackpill_f411ce/blackpill_f411ce.dts:138 */
		};

		/* node '/clocks/pll' defined in zephyr/dts/arm/st/f4/stm32f4.dtsi:90 */
		pll: pll {
			#clock-cells = < 0x0 >;              /* in zephyr/dts/arm/st/f4/stm32f4.dtsi:91 */
			compatible = "st,stm32fx-pll-clock"; /* in zephyr/dts/arm/st/f4/stm32f4.dtsi:92 */
			div-m = < 0x19 >;                    /* in zephyr/boards/weact/blackpill_f411ce/blackpill_f411ce.dts:147 */
			mul-n = < 0xc0 >;                    /* in zephyr/boards/weact/blackpill_f411ce/blackpill_f411ce.dts:148 */
			div-p = < 0x2 >;                     /* in zephyr/boards/weact/blackpill_f411ce/blackpill_f411ce.dts:149 */
			div-q = < 0x4 >;                     /* in zephyr/boards/weact/blackpill_f411ce/blackpill_f411ce.dts:150 */
			clocks = < &clk_hse >;               /* in zephyr/boards/weact/blackpill_f411ce/blackpill_f411ce.dts:151 */
			status = "okay";                     /* in zephyr/boards/weact/blackpill_f411ce/blackpill_f411ce.dts:152 */
			phandle = < 0x2 >;                   /* in zephyr/boards/weact/blackpill_f411ce/blackpill_f411ce.dts:156 */
		};

		/* node '/clocks/plli2s' defined in zephyr/dts/arm/st/f4/stm32f401.dtsi:11 */
		plli2s: plli2s {
			#clock-cells = < 0x0 >;              /* in zephyr/dts/arm/st/f4/stm32f401.dtsi:12 */
			compatible = "st,stm32fx-pll-clock"; /* in zephyr/dts/arm/st/f4/stm32f401.dtsi:13 */
			status = "disabled";                 /* in zephyr/dts/arm/st/f4/stm32f401.dtsi:14 */
		};
	};

	/* node '/mcos' defined in zephyr/dts/arm/st/f4/stm32f4.dtsi:97 */
	mcos {

		/* node '/mcos/mco1' defined in zephyr/dts/arm/st/f4/stm32f4.dtsi:98 */
		mco1: mco1 {
			compatible = "st,stm32-clock-mco"; /* in zephyr/dts/arm/st/f4/stm32f4.dtsi:99 */
			clock-names = "clksel";            /* in zephyr/dts/arm/st/f4/stm32f4.dtsi:100 */
			status = "disabled";               /* in zephyr/dts/arm/st/f4/stm32f4.dtsi:101 */
		};

		/* node '/mcos/mco2' defined in zephyr/dts/arm/st/f4/stm32f4.dtsi:104 */
		mco2: mco2 {
			compatible = "st,stm32-clock-mco"; /* in zephyr/dts/arm/st/f4/stm32f4.dtsi:105 */
			clock-names = "clksel";            /* in zephyr/dts/arm/st/f4/stm32f4.dtsi:106 */
			status = "disabled";               /* in zephyr/dts/arm/st/f4/stm32f4.dtsi:107 */
		};
	};

	/* node '/power@40007000' defined in zephyr/dts/arm/st/f4/stm32f4.dtsi:654 */
	pwr: power@40007000 {
		compatible = "st,stm32-pwr"; /* in zephyr/dts/arm/st/f4/stm32f4.dtsi:655 */
		reg = < 0x40007000 0x400 >;  /* in zephyr/dts/arm/st/f4/stm32f4.dtsi:656 */
		status = "disabled";         /* in zephyr/dts/arm/st/f4/stm32f4.dtsi:657 */
		wkup-pins-nb = < 0x1 >;      /* in zephyr/dts/arm/st/f4/stm32f4.dtsi:659 */
		#address-cells = < 0x1 >;    /* in zephyr/dts/arm/st/f4/stm32f4.dtsi:661 */
		#size-cells = < 0x0 >;       /* in zephyr/dts/arm/st/f4/stm32f4.dtsi:662 */

		/* node '/power@40007000/wkup-pin@1' defined in zephyr/dts/arm/st/f4/stm32f4.dtsi:664 */
		wkup-pin@1 {
			reg = < 0x1 >;                   /* in zephyr/dts/arm/st/f4/stm32f4.dtsi:665 */
			wkup-gpios = < &gpioa 0x0 0x1 >; /* in zephyr/dts/arm/st/f4/stm32f4.dtsi:666 */
		};
	};

	/* node '/dietemp' defined in zephyr/dts/arm/st/f4/stm32f4.dtsi:670 */
	die_temp: dietemp {
		compatible = "st,stm32-temp-cal"; /* in zephyr/dts/arm/st/f4/stm32f4.dtsi:671 */
		nvmem-cells = < &ts_cal1_otp >,
		              < &ts_cal2_otp >;   /* in zephyr/dts/arm/st/f4/stm32f4.dtsi:672 */
		nvmem-cell-names = "TS_CAL1",
		                   "TS_CAL2";     /* in zephyr/dts/arm/st/f4/stm32f4.dtsi:673 */
		ts-cal1-temp = < 0x1e >;          /* in zephyr/dts/arm/st/f4/stm32f4.dtsi:674 */
		ts-cal2-temp = < 0x6e >;          /* in zephyr/dts/arm/st/f4/stm32f4.dtsi:675 */
		ts-cal-vrefanalog = < 0xce4 >;    /* in zephyr/dts/arm/st/f4/stm32f4.dtsi:676 */
		status = "disabled";              /* in zephyr/dts/arm/st/f4/stm32f4.dtsi:678 */
		io-channels = < &adc1 0x12 >;     /* in zephyr/dts/arm/st/f4/stm32f411.dtsi:65 */
	};

	/* node '/vref' defined in zephyr/dts/arm/st/f4/stm32f4.dtsi:681 */
	vref: vref {
		compatible = "st,stm32-vref";   /* in zephyr/dts/arm/st/f4/stm32f4.dtsi:682 */
		nvmem-cells = < &vrefint_otp >; /* in zephyr/dts/arm/st/f4/stm32f4.dtsi:683 */
		vrefint-cal-mv = < 0xce4 >;     /* in zephyr/dts/arm/st/f4/stm32f4.dtsi:684 */
		io-channels = < &adc1 0x11 >;   /* in zephyr/dts/arm/st/f4/stm32f4.dtsi:685 */
		status = "okay";                /* in zephyr/boards/weact/blackpill_f411ce/blackpill_f411ce.dts:164 */
	};

	/* node '/vbat' defined in zephyr/dts/arm/st/f4/stm32f4.dtsi:689 */
	vbat: vbat {
		compatible = "st,stm32-vbat"; /* in zephyr/dts/arm/st/f4/stm32f4.dtsi:690 */
		ratio = < 0x4 >;              /* in zephyr/dts/arm/st/f4/stm32f4.dtsi:691 */
		io-channels = < &adc1 0x12 >; /* in zephyr/dts/arm/st/f4/stm32f4.dtsi:692 */
		status = "okay";              /* in zephyr/boards/weact/blackpill_f411ce/blackpill_f411ce.dts:168 */
	};

	/* node '/otgfs_phy' defined in zephyr/dts/arm/st/f4/stm32f4.dtsi:696 */
	otgfs_phy: otgfs_phy {
		compatible = "usb-nop-xceiv"; /* in zephyr/dts/arm/st/f4/stm32f4.dtsi:697 */
		#phy-cells = < 0x0 >;         /* in zephyr/dts/arm/st/f4/stm32f4.dtsi:698 */
		phandle = < 0x11 >;           /* in zephyr/dts/arm/st/f4/stm32f4.dtsi:370 */
	};

	/* node '/smbus1' defined in zephyr/dts/arm/st/f4/stm32f4.dtsi:701 */
	smbus1: smbus1 {
		compatible = "st,stm32-smbus"; /* in zephyr/dts/arm/st/f4/stm32f4.dtsi:702 */
		#address-cells = < 0x1 >;      /* in zephyr/dts/arm/st/f4/stm32f4.dtsi:703 */
		#size-cells = < 0x0 >;         /* in zephyr/dts/arm/st/f4/stm32f4.dtsi:704 */
		i2c = < &i2c1 >;               /* in zephyr/dts/arm/st/f4/stm32f4.dtsi:705 */
		status = "disabled";           /* in zephyr/dts/arm/st/f4/stm32f4.dtsi:706 */
	};

	/* node '/smbus2' defined in zephyr/dts/arm/st/f4/stm32f4.dtsi:709 */
	smbus2: smbus2 {
		compatible = "st,stm32-smbus"; /* in zephyr/dts/arm/st/f4/stm32f4.dtsi:710 */
		#address-cells = < 0x1 >;      /* in zephyr/dts/arm/st/f4/stm32f4.dtsi:711 */
		#size-cells = < 0x0 >;         /* in zephyr/dts/arm/st/f4/stm32f4.dtsi:712 */
		i2c = < &i2c2 >;               /* in zephyr/dts/arm/st/f4/stm32f4.dtsi:713 */
		status = "disabled";           /* in zephyr/dts/arm/st/f4/stm32f4.dtsi:714 */
	};

	/* node '/smbus3' defined in zephyr/dts/arm/st/f4/stm32f4.dtsi:717 */
	smbus3: smbus3 {
		compatible = "st,stm32-smbus"; /* in zephyr/dts/arm/st/f4/stm32f4.dtsi:718 */
		#address-cells = < 0x1 >;      /* in zephyr/dts/arm/st/f4/stm32f4.dtsi:719 */
		#size-cells = < 0x0 >;         /* in zephyr/dts/arm/st/f4/stm32f4.dtsi:720 */
		i2c = < &i2c3 >;               /* in zephyr/dts/arm/st/f4/stm32f4.dtsi:721 */
		status = "disabled";           /* in zephyr/dts/arm/st/f4/stm32f4.dtsi:722 */
	};

	/* node '/leds' defined in zephyr/boards/weact/blackpill_f411ce/blackpill_f411ce.dts:24 */
	leds {
		compatible = "gpio-leds"; /* in zephyr/boards/weact/blackpill_f411ce/blackpill_f411ce.dts:25 */

		/* node '/leds/led' defined in zephyr/boards/weact/blackpill_f411ce/blackpill_f411ce.dts:27 */
		user_led: led {
			gpios = < &gpioc 0xd 0x1 >; /* in zephyr/boards/weact/blackpill_f411ce/blackpill_f411ce.dts:28 */
			label = "User LED";         /* in zephyr/boards/weact/blackpill_f411ce/blackpill_f411ce.dts:29 */
		};
	};

	/* node '/gpio_keys' defined in zephyr/boards/weact/blackpill_f411ce/blackpill_f411ce.dts:33 */
	gpio_keys {
		compatible = "gpio-keys"; /* in zephyr/boards/weact/blackpill_f411ce/blackpill_f411ce.dts:34 */

		/* node '/gpio_keys/button' defined in zephyr/boards/weact/blackpill_f411ce/blackpill_f411ce.dts:36 */
		user_button: button {
			label = "KEY";               /* in zephyr/boards/weact/blackpill_f411ce/blackpill_f411ce.dts:37 */
			gpios = < &gpioa 0x0 0x11 >; /* in zephyr/boards/weact/blackpill_f411ce/blackpill_f411ce.dts:38 */
			zephyr,code = < 0xb >;       /* in zephyr/boards/weact/blackpill_f411ce/blackpill_f411ce.dts:39 */
		};
	};

	/* node '/servo' defined in joint_microros_tmc2209_gripper_as5600/boards/blackpill_f411ce.overlay:87 */
	servo: servo {
		compatible = "pwm-servo";           /* in joint_microros_tmc2209_gripper_as5600/boards/blackpill_f411ce.overlay:88 */
		pwms = < &pwm4 0x3 0x1312d00 0x0 >; /* in joint_microros_tmc2209_gripper_as5600/boards/blackpill_f411ce.overlay:89 */
		min-pulse = < 0xaae60 >;            /* in joint_microros_tmc2209_gripper_as5600/boards/blackpill_f411ce.overlay:90 */
		max-pulse = < 0x231860 >;           /* in joint_microros_tmc2209_gripper_as5600/boards/blackpill_f411ce.overlay:91 */
	};

	/* node '/tmc2209_m0' defined in joint_microros_tmc2209_gripper_as5600/boards/blackpill_f411ce.overlay:94 */
	tmc2209_m0: tmc2209_m0 {
		compatible = "adi,tmc2209";    /* in joint_microros_tmc2209_gripper_as5600/boards/blackpill_f411ce.overlay:95 */
		en-gpios = < &gpioc 0xd 0x0 >; /* in joint_microros_tmc2209_gripper_as5600/boards/blackpill_f411ce.overlay:96 */
		micro-step-res = < 0x20 >;     /* in joint_microros_tmc2209_gripper_as5600/boards/blackpill_f411ce.overlay:97 */
		phandle = < 0x24 >;            /* in joint_microros_tmc2209_gripper_as5600/boards/blackpill_f411ce.overlay:117 */
	};

	/* node '/tmc2209_m1' defined in joint_microros_tmc2209_gripper_as5600/boards/blackpill_f411ce.overlay:100 */
	tmc2209_m1: tmc2209_m1 {
		compatible = "adi,tmc2209";    /* in joint_microros_tmc2209_gripper_as5600/boards/blackpill_f411ce.overlay:101 */
		en-gpios = < &gpioc 0xd 0x0 >; /* in joint_microros_tmc2209_gripper_as5600/boards/blackpill_f411ce.overlay:102 */
		micro-step-res = < 0x20 >;     /* in joint_microros_tmc2209_gripper_as5600/boards/blackpill_f411ce.overlay:103 */
		phandle = < 0x25 >;            /* in joint_microros_tmc2209_gripper_as5600/boards/blackpill_f411ce.overlay:125 */
	};

	/* node '/tmc2209_m2' defined in joint_microros_tmc2209_gripper_as5600/boards/blackpill_f411ce.overlay:106 */
	tmc2209_m2: tmc2209_m2 {
		compatible = "adi,tmc2209";    /* in joint_microros_tmc2209_gripper_as5600/boards/blackpill_f411ce.overlay:107 */
		en-gpios = < &gpioc 0xd 0x0 >; /* in joint_microros_tmc2209_gripper_as5600/boards/blackpill_f411ce.overlay:108 */
		micro-step-res = < 0x20 >;     /* in joint_microros_tmc2209_gripper_as5600/boards/blackpill_f411ce.overlay:109 */
		phandle = < 0x26 >;            /* in joint_microros_tmc2209_gripper_as5600/boards/blackpill_f411ce.overlay:133 */
	};

	/* node '/stepper0' defined in joint_microros_tmc2209_gripper_as5600/boards/blackpill_f411ce.overlay:112 */
	stepper0_control: stepper0 {
		compatible = "zephyr,gpio-step-dir-stepper-ctrl"; /* in joint_microros_tmc2209_gripper_as5600/boards/blackpill_f411ce.overlay:113 */
		status = "okay";                                  /* in joint_microros_tmc2209_gripper_as5600/boards/blackpill_f411ce.overlay:114 */
		step-gpios = < &gpioa 0x6 0x0 >;                  /* in joint_microros_tmc2209_gripper_as5600/boards/blackpill_f411ce.overlay:115 */
		dir-gpios = < &gpioa 0x7 0x0 >;                   /* in joint_microros_tmc2209_gripper_as5600/boards/blackpill_f411ce.overlay:116 */
		stepper-driver = < &tmc2209_m0 >;                 /* in joint_microros_tmc2209_gripper_as5600/boards/blackpill_f411ce.overlay:117 */
	};

	/* node '/stepper1' defined in joint_microros_tmc2209_gripper_as5600/boards/blackpill_f411ce.overlay:120 */
	stepper1_control: stepper1 {
		compatible = "zephyr,gpio-step-dir-stepper-ctrl"; /* in joint_microros_tmc2209_gripper_as5600/boards/blackpill_f411ce.overlay:121 */
		status = "okay";                                  /* in joint_microros_tmc2209_gripper_as5600/boards/blackpill_f411ce.overlay:122 */
		step-gpios = < &gpioa 0x0 0x0 >;                  /* in joint_microros_tmc2209_gripper_as5600/boards/blackpill_f411ce.overlay:123 */
		dir-gpios = < &gpioa 0x1 0x0 >;                   /* in joint_microros_tmc2209_gripper_as5600/boards/blackpill_f411ce.overlay:124 */
		stepper-driver = < &tmc2209_m1 >;                 /* in joint_microros_tmc2209_gripper_as5600/boards/blackpill_f411ce.overlay:125 */
	};

	/* node '/stepper2' defined in joint_microros_tmc2209_gripper_as5600/boards/blackpill_f411ce.overlay:128 */
	stepper2_control: stepper2 {
		compatible = "zephyr,gpio-step-dir-stepper-ctrl"; /* in joint_microros_tmc2209_gripper_as5600/boards/blackpill_f411ce.overlay:129 */
		status = "okay";                                  /* in joint_microros_tmc2209_gripper_as5600/boards/blackpill_f411ce.overlay:130 */
		step-gpios = < &gpioa 0x3 0x0 >;                  /* in joint_microros_tmc2209_gripper_as5600/boards/blackpill_f411ce.overlay:131 */
		dir-gpios = < &gpioa 0x5 0x0 >;                   /* in joint_microros_tmc2209_gripper_as5600/boards/blackpill_f411ce.overlay:132 */
		stepper-driver = < &tmc2209_m2 >;                 /* in joint_microros_tmc2209_gripper_as5600/boards/blackpill_f411ce.overlay:133 */
	};
};
